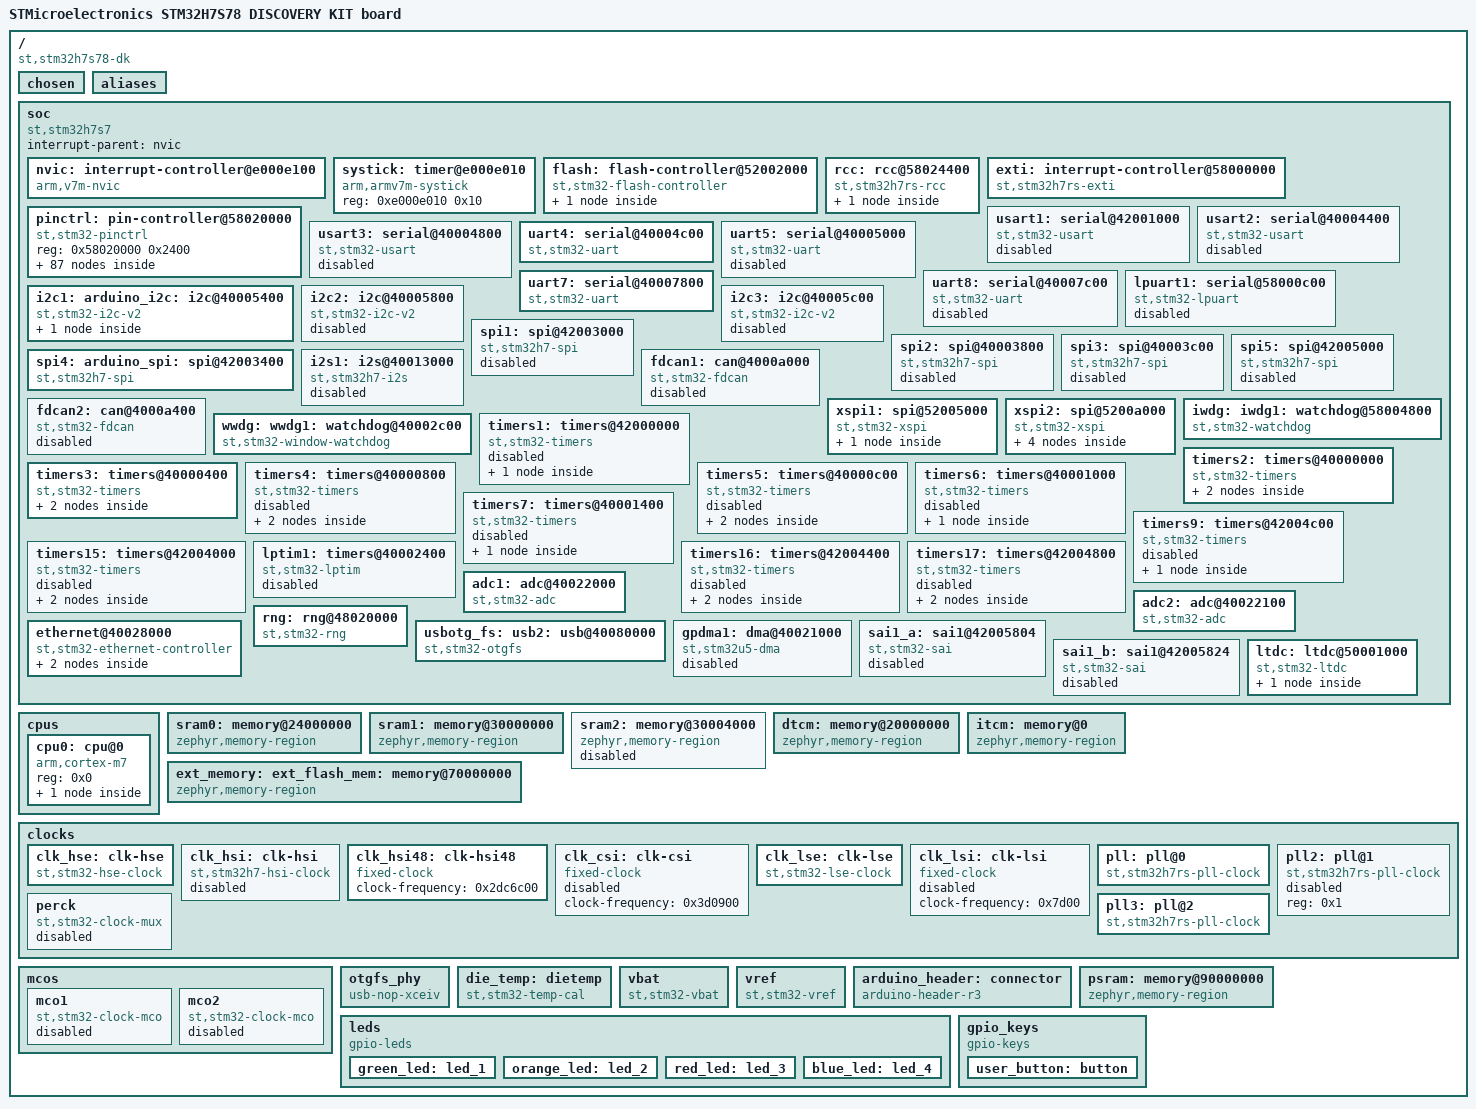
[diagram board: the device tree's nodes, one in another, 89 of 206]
/dts-v1/;

/* node '/' defined in zephyr/dts/common/skeleton.dtsi:9 */
/ {
	#address-cells = < 0x1 >;                                    /* in zephyr/dts/common/skeleton.dtsi:10 */
	#size-cells = < 0x1 >;                                       /* in zephyr/dts/common/skeleton.dtsi:11 */
	model = "STMicroelectronics STM32H7S78 DISCOVERY KIT board"; /* in zephyr/boards/st/stm32h7s78_dk/stm32h7s78_dk.dts:11 */
	compatible = "st,stm32h7s78-dk";                             /* in zephyr/boards/st/stm32h7s78_dk/stm32h7s78_dk.dts:12 */

	/* node '/chosen' defined in zephyr/dts/common/skeleton.dtsi:13 */
	chosen {
		zephyr,entropy = &rng;            /* in zephyr/dts/arm/st/h7rs/stm32h7rs.dtsi:30 */
		zephyr,console = &uart4;          /* in zephyr/boards/st/stm32h7s78_dk/stm32h7s78_dk-common.dtsi:16 */
		zephyr,shell-uart = &uart4;       /* in zephyr/boards/st/stm32h7s78_dk/stm32h7s78_dk-common.dtsi:17 */
		zephyr,sram = &sram0;             /* in zephyr/boards/st/stm32h7s78_dk/stm32h7s78_dk-common.dtsi:18 */
		zephyr,display = &ltdc;           /* in zephyr/boards/st/stm32h7s78_dk/stm32h7s78_dk-common.dtsi:19 */
		zephyr,touch = &display_ctp;      /* in zephyr/boards/st/stm32h7s78_dk/stm32h7s78_dk-common.dtsi:20 */
		zephyr,flash = &flash0;           /* in zephyr/boards/st/stm32h7s78_dk/stm32h7s78_dk.dts:15 */
		zephyr,flash-controller = &flash; /* in zephyr/boards/st/stm32h7s78_dk/stm32h7s78_dk.dts:16 */
	};

	/* node '/aliases' defined in zephyr/dts/common/skeleton.dtsi:15 */
	aliases {
		led0 = &blue_led;         /* in zephyr/boards/st/stm32h7s78_dk/stm32h7s78_dk-common.dtsi:65 */
		sw0 = &user_button;       /* in zephyr/boards/st/stm32h7s78_dk/stm32h7s78_dk-common.dtsi:66 */
		watchdog0 = &iwdg;        /* in zephyr/boards/st/stm32h7s78_dk/stm32h7s78_dk-common.dtsi:67 */
		die-temp0 = &die_temp;    /* in zephyr/boards/st/stm32h7s78_dk/stm32h7s78_dk-common.dtsi:68 */
		volt-sensor0 = &vref;     /* in zephyr/boards/st/stm32h7s78_dk/stm32h7s78_dk-common.dtsi:69 */
		volt-sensor1 = &vbat;     /* in zephyr/boards/st/stm32h7s78_dk/stm32h7s78_dk-common.dtsi:70 */
		spi-flash0 = &mx66uw1g45; /* in zephyr/boards/st/stm32h7s78_dk/stm32h7s78_dk-common.dtsi:71 */
	};

	/* node '/soc' defined in zephyr/dts/arm/armv7-m.dtsi:6 */
	soc {
		#address-cells = < 0x1 >;     /* in zephyr/dts/arm/armv7-m.dtsi:7 */
		#size-cells = < 0x1 >;        /* in zephyr/dts/arm/armv7-m.dtsi:8 */
		interrupt-parent = < &nvic >; /* in zephyr/dts/arm/armv7-m.dtsi:10 */
		ranges;                       /* in zephyr/dts/arm/armv7-m.dtsi:11 */
		compatible = "st,stm32h7s7",
		             "st,stm32h7rs",
		             "simple-bus";    /* in zephyr/dts/arm/st/h7rs/stm32h7s7.dtsi:14 */

		/* node '/soc/interrupt-controller@e000e100' defined in zephyr/dts/arm/armv7-m.dtsi:13 */
		nvic: interrupt-controller@e000e100 {
			#address-cells = < 0x1 >;            /* in zephyr/dts/arm/armv7-m.dtsi:14 */
			compatible = "arm,v7m-nvic";         /* in zephyr/dts/arm/armv7-m.dtsi:15 */
			reg = < 0xe000e100 0xc00 >;          /* in zephyr/dts/arm/armv7-m.dtsi:16 */
			interrupt-controller;                /* in zephyr/dts/arm/armv7-m.dtsi:17 */
			#interrupt-cells = < 0x2 >;          /* in zephyr/dts/arm/armv7-m.dtsi:18 */
			arm,num-irq-priority-bits = < 0x4 >; /* in zephyr/dts/arm/st/h7rs/stm32h7rs.dtsi:985 */
			phandle = < 0x1 >;                   /* in zephyr/dts/arm/armv7-m.dtsi:10 */
		};

		/* node '/soc/timer@e000e010' defined in zephyr/dts/arm/armv7-m.dtsi:21 */
		systick: timer@e000e010 {
			compatible = "arm,armv7m-systick"; /* in zephyr/dts/arm/armv7-m.dtsi:22 */
			reg = < 0xe000e010 0x10 >;         /* in zephyr/dts/arm/armv7-m.dtsi:23 */
		};

		/* node '/soc/flash-controller@52002000' defined in zephyr/dts/arm/st/h7rs/stm32h7rs.dtsi:187 */
		flash: flash-controller@52002000 {
			compatible = "st,stm32-flash-controller",
			             "st,stm32h7-flash-controller"; /* in zephyr/dts/arm/st/h7rs/stm32h7rs.dtsi:188 */
			reg = < 0x52002000 0x400 >;                 /* in zephyr/dts/arm/st/h7rs/stm32h7rs.dtsi:189 */
			interrupts = < 0x8 0x0 >;                   /* in zephyr/dts/arm/st/h7rs/stm32h7rs.dtsi:190 */
			#address-cells = < 0x1 >;                   /* in zephyr/dts/arm/st/h7rs/stm32h7rs.dtsi:192 */
			#size-cells = < 0x1 >;                      /* in zephyr/dts/arm/st/h7rs/stm32h7rs.dtsi:193 */

			/* node '/soc/flash-controller@52002000/flash@8000000' defined in zephyr/dts/arm/st/h7rs/stm32h7rs.dtsi:195 */
			flash0: flash@8000000 {
				compatible = "st,stm32-nv-flash",
				             "soc-nv-flash";      /* in zephyr/dts/arm/st/h7rs/stm32h7rs.dtsi:196 */
				write-block-size = < 0x20 >;      /* in zephyr/dts/arm/st/h7rs/stm32h7rs.dtsi:197 */
				erase-block-size = < 0x2000 >;    /* in zephyr/dts/arm/st/h7rs/stm32h7rs.dtsi:198 */
				max-erase-time = < 0x3 >;         /* in zephyr/dts/arm/st/h7rs/stm32h7rs.dtsi:200 */
				reg = < 0x8000000 0x10000 >;      /* in zephyr/dts/arm/st/h7rs/stm32h7s7X8.dtsi:13 */
			};
		};

		/* node '/soc/rcc@58024400' defined in zephyr/dts/arm/st/h7rs/stm32h7rs.dtsi:204 */
		rcc: rcc@58024400 {
			compatible = "st,stm32h7rs-rcc"; /* in zephyr/dts/arm/st/h7rs/stm32h7rs.dtsi:205 */
			#clock-cells = < 0x2 >;          /* in zephyr/dts/arm/st/h7rs/stm32h7rs.dtsi:206 */
			reg = < 0x58024400 0x400 >;      /* in zephyr/dts/arm/st/h7rs/stm32h7rs.dtsi:207 */
			clocks = < &pll >;               /* in zephyr/boards/st/stm32h7s78_dk/stm32h7s78_dk-common.dtsi:118 */
			clock-frequency = < 0xee6b280 >; /* in zephyr/boards/st/stm32h7s78_dk/stm32h7s78_dk-common.dtsi:119 */
			dcpre = < 0x1 >;                 /* in zephyr/boards/st/stm32h7s78_dk/stm32h7s78_dk-common.dtsi:120 */
			hpre = < 0x1 >;                  /* in zephyr/boards/st/stm32h7s78_dk/stm32h7s78_dk-common.dtsi:121 */
			ppre1 = < 0x2 >;                 /* in zephyr/boards/st/stm32h7s78_dk/stm32h7s78_dk-common.dtsi:122 */
			ppre2 = < 0x2 >;                 /* in zephyr/boards/st/stm32h7s78_dk/stm32h7s78_dk-common.dtsi:123 */
			ppre4 = < 0x2 >;                 /* in zephyr/boards/st/stm32h7s78_dk/stm32h7s78_dk-common.dtsi:124 */
			ppre5 = < 0x2 >;                 /* in zephyr/boards/st/stm32h7s78_dk/stm32h7s78_dk-common.dtsi:125 */
			phandle = < 0x3 >;               /* in zephyr/dts/arm/st/h7rs/stm32h7rs.dtsi:221 */

			/* node '/soc/rcc@58024400/reset-controller' defined in zephyr/dts/arm/st/h7rs/stm32h7rs.dtsi:209 */
			rctl: reset-controller {
				compatible = "st,stm32-rcc-rctl"; /* in zephyr/dts/arm/st/h7rs/stm32h7rs.dtsi:210 */
				#reset-cells = < 0x1 >;           /* in zephyr/dts/arm/st/h7rs/stm32h7rs.dtsi:211 */
				phandle = < 0x4 >;                /* in zephyr/dts/arm/st/h7rs/stm32h7rs.dtsi:345 */
			};
		};

		/* node '/soc/interrupt-controller@58000000' defined in zephyr/dts/arm/st/h7rs/stm32h7rs.dtsi:215 */
		exti: interrupt-controller@58000000 {
			compatible = "st,stm32h7rs-exti",
			             "st,stm32-exti";     /* in zephyr/dts/arm/st/h7rs/stm32h7rs.dtsi:216 */
			interrupt-controller;             /* in zephyr/dts/arm/st/h7rs/stm32h7rs.dtsi:217 */
			#interrupt-cells = < 0x1 >;       /* in zephyr/dts/arm/st/h7rs/stm32h7rs.dtsi:218 */
			#address-cells = < 0x0 >;         /* in zephyr/dts/arm/st/h7rs/stm32h7rs.dtsi:219 */
			reg = < 0x58000000 0x400 >;       /* in zephyr/dts/arm/st/h7rs/stm32h7rs.dtsi:220 */
			clocks = < &rcc 0x154 0x2 >;      /* in zephyr/dts/arm/st/h7rs/stm32h7rs.dtsi:221 */
			num-lines = < 0x40 >;             /* in zephyr/dts/arm/st/h7rs/stm32h7rs.dtsi:223 */
			interrupts = < 0x10 0x0 >,
			             < 0x11 0x0 >,
			             < 0x12 0x0 >,
			             < 0x13 0x0 >,
			             < 0x14 0x0 >,
			             < 0x15 0x0 >,
			             < 0x16 0x0 >,
			             < 0x17 0x0 >,
			             < 0x18 0x0 >,
			             < 0x19 0x0 >,
			             < 0x1a 0x0 >,
			             < 0x1b 0x0 >,
			             < 0x1c 0x0 >,
			             < 0x1d 0x0 >,
			             < 0x1e 0x0 >,
			             < 0x1f 0x0 >;        /* in zephyr/dts/arm/st/h7rs/stm32h7rs.dtsi:224 */
			interrupt-names = "line0",
			                  "line1",
			                  "line2",
			                  "line3",
			                  "line4",
			                  "line5",
			                  "line6",
			                  "line7",
			                  "line8",
			                  "line9",
			                  "line10",
			                  "line11",
			                  "line12",
			                  "line13",
			                  "line14",
			                  "line15";       /* in zephyr/dts/arm/st/h7rs/stm32h7rs.dtsi:228 */
			line-ranges = < 0x0 0x1 >,
			              < 0x1 0x1 >,
			              < 0x2 0x1 >,
			              < 0x3 0x1 >,
			              < 0x4 0x1 >,
			              < 0x5 0x1 >,
			              < 0x6 0x1 >,
			              < 0x7 0x1 >,
			              < 0x8 0x1 >,
			              < 0x9 0x1 >,
			              < 0xa 0x1 >,
			              < 0xb 0x1 >,
			              < 0xc 0x1 >,
			              < 0xd 0x1 >,
			              < 0xe 0x1 >,
			              < 0xf 0x1 >;        /* in zephyr/dts/arm/st/h7rs/stm32h7rs.dtsi:232 */
		};

		/* node '/soc/pin-controller@58020000' defined in zephyr/dts/arm/st/h7rs/stm32h7rs.dtsi:238 */
		pinctrl: pin-controller@58020000 {
			compatible = "st,stm32-pinctrl"; /* in zephyr/dts/arm/st/h7rs/stm32h7rs.dtsi:239 */
			#address-cells = < 0x1 >;        /* in zephyr/dts/arm/st/h7rs/stm32h7rs.dtsi:240 */
			#size-cells = < 0x1 >;           /* in zephyr/dts/arm/st/h7rs/stm32h7rs.dtsi:241 */
			reg = < 0x58020000 0x2400 >;     /* in zephyr/dts/arm/st/h7rs/stm32h7rs.dtsi:242 */

			/* node '/soc/pin-controller@58020000/gpio@58020000' defined in zephyr/dts/arm/st/h7rs/stm32h7rs.dtsi:244 */
			gpioa: gpio@58020000 {
				compatible = "st,stm32-gpio"; /* in zephyr/dts/arm/st/h7rs/stm32h7rs.dtsi:245 */
				gpio-controller;              /* in zephyr/dts/arm/st/h7rs/stm32h7rs.dtsi:246 */
				#gpio-cells = < 0x2 >;        /* in zephyr/dts/arm/st/h7rs/stm32h7rs.dtsi:247 */
				reg = < 0x58020000 0x400 >;   /* in zephyr/dts/arm/st/h7rs/stm32h7rs.dtsi:248 */
				clocks = < &rcc 0x140 0x1 >;  /* in zephyr/dts/arm/st/h7rs/stm32h7rs.dtsi:249 */
			};

			/* node '/soc/pin-controller@58020000/gpio@58020400' defined in zephyr/dts/arm/st/h7rs/stm32h7rs.dtsi:252 */
			gpiob: gpio@58020400 {
				compatible = "st,stm32-gpio"; /* in zephyr/dts/arm/st/h7rs/stm32h7rs.dtsi:253 */
				gpio-controller;              /* in zephyr/dts/arm/st/h7rs/stm32h7rs.dtsi:254 */
				#gpio-cells = < 0x2 >;        /* in zephyr/dts/arm/st/h7rs/stm32h7rs.dtsi:255 */
				reg = < 0x58020400 0x400 >;   /* in zephyr/dts/arm/st/h7rs/stm32h7rs.dtsi:256 */
				clocks = < &rcc 0x140 0x2 >;  /* in zephyr/dts/arm/st/h7rs/stm32h7rs.dtsi:257 */
				phandle = < 0x5a >;           /* in zephyr/boards/st/stm32h7s78_dk/arduino_r3_connector.dtsi:15 */
			};

			/* node '/soc/pin-controller@58020000/gpio@58020800' defined in zephyr/dts/arm/st/h7rs/stm32h7rs.dtsi:260 */
			gpioc: gpio@58020800 {
				compatible = "st,stm32-gpio"; /* in zephyr/dts/arm/st/h7rs/stm32h7rs.dtsi:261 */
				gpio-controller;              /* in zephyr/dts/arm/st/h7rs/stm32h7rs.dtsi:262 */
				#gpio-cells = < 0x2 >;        /* in zephyr/dts/arm/st/h7rs/stm32h7rs.dtsi:263 */
				reg = < 0x58020800 0x400 >;   /* in zephyr/dts/arm/st/h7rs/stm32h7rs.dtsi:264 */
				clocks = < &rcc 0x140 0x4 >;  /* in zephyr/dts/arm/st/h7rs/stm32h7rs.dtsi:265 */
				phandle = < 0x57 >;           /* in zephyr/boards/st/stm32h7s78_dk/arduino_r3_connector.dtsi:15 */
			};

			/* node '/soc/pin-controller@58020000/gpio@58020C00' defined in zephyr/dts/arm/st/h7rs/stm32h7rs.dtsi:268 */
			gpiod: gpio@58020C00 {
				compatible = "st,stm32-gpio"; /* in zephyr/dts/arm/st/h7rs/stm32h7rs.dtsi:269 */
				gpio-controller;              /* in zephyr/dts/arm/st/h7rs/stm32h7rs.dtsi:270 */
				#gpio-cells = < 0x2 >;        /* in zephyr/dts/arm/st/h7rs/stm32h7rs.dtsi:271 */
				reg = < 0x58020c00 0x400 >;   /* in zephyr/dts/arm/st/h7rs/stm32h7rs.dtsi:272 */
				clocks = < &rcc 0x140 0x8 >;  /* in zephyr/dts/arm/st/h7rs/stm32h7rs.dtsi:273 */
				phandle = < 0x59 >;           /* in zephyr/boards/st/stm32h7s78_dk/arduino_r3_connector.dtsi:15 */
			};

			/* node '/soc/pin-controller@58020000/gpio@58021000' defined in zephyr/dts/arm/st/h7rs/stm32h7rs.dtsi:276 */
			gpioe: gpio@58021000 {
				compatible = "st,stm32-gpio"; /* in zephyr/dts/arm/st/h7rs/stm32h7rs.dtsi:277 */
				gpio-controller;              /* in zephyr/dts/arm/st/h7rs/stm32h7rs.dtsi:278 */
				#gpio-cells = < 0x2 >;        /* in zephyr/dts/arm/st/h7rs/stm32h7rs.dtsi:279 */
				reg = < 0x58021000 0x400 >;   /* in zephyr/dts/arm/st/h7rs/stm32h7rs.dtsi:280 */
				clocks = < &rcc 0x140 0x10 >; /* in zephyr/dts/arm/st/h7rs/stm32h7rs.dtsi:281 */
				phandle = < 0xb >;            /* in zephyr/boards/st/stm32h7s78_dk/stm32h7s78_dk-common.dtsi:207 */
			};

			/* node '/soc/pin-controller@58020000/gpio@58021400' defined in zephyr/dts/arm/st/h7rs/stm32h7rs.dtsi:284 */
			gpiof: gpio@58021400 {
				compatible = "st,stm32-gpio"; /* in zephyr/dts/arm/st/h7rs/stm32h7rs.dtsi:285 */
				gpio-controller;              /* in zephyr/dts/arm/st/h7rs/stm32h7rs.dtsi:286 */
				#gpio-cells = < 0x2 >;        /* in zephyr/dts/arm/st/h7rs/stm32h7rs.dtsi:287 */
				reg = < 0x58021400 0x400 >;   /* in zephyr/dts/arm/st/h7rs/stm32h7rs.dtsi:288 */
				clocks = < &rcc 0x140 0x20 >; /* in zephyr/dts/arm/st/h7rs/stm32h7rs.dtsi:289 */
				phandle = < 0x58 >;           /* in zephyr/boards/st/stm32h7s78_dk/arduino_r3_connector.dtsi:15 */
			};

			/* node '/soc/pin-controller@58020000/gpio@58021800' defined in zephyr/dts/arm/st/h7rs/stm32h7rs.dtsi:292 */
			gpiog: gpio@58021800 {
				compatible = "st,stm32-gpio"; /* in zephyr/dts/arm/st/h7rs/stm32h7rs.dtsi:293 */
				gpio-controller;              /* in zephyr/dts/arm/st/h7rs/stm32h7rs.dtsi:294 */
				#gpio-cells = < 0x2 >;        /* in zephyr/dts/arm/st/h7rs/stm32h7rs.dtsi:295 */
				reg = < 0x58021800 0x400 >;   /* in zephyr/dts/arm/st/h7rs/stm32h7rs.dtsi:296 */
				clocks = < &rcc 0x140 0x40 >; /* in zephyr/dts/arm/st/h7rs/stm32h7rs.dtsi:297 */
				phandle = < 0x53 >;           /* in zephyr/boards/st/stm32h7s78_dk/stm32h7s78_dk-common.dtsi:310 */
			};

			/* node '/soc/pin-controller@58020000/gpio@58021c00' defined in zephyr/dts/arm/st/h7rs/stm32h7rs.dtsi:300 */
			gpioh: gpio@58021c00 {
				compatible = "st,stm32-gpio"; /* in zephyr/dts/arm/st/h7rs/stm32h7rs.dtsi:301 */
				gpio-controller;              /* in zephyr/dts/arm/st/h7rs/stm32h7rs.dtsi:302 */
				#gpio-cells = < 0x2 >;        /* in zephyr/dts/arm/st/h7rs/stm32h7rs.dtsi:303 */
				reg = < 0x58021c00 0x400 >;   /* in zephyr/dts/arm/st/h7rs/stm32h7rs.dtsi:304 */
				clocks = < &rcc 0x140 0x80 >; /* in zephyr/dts/arm/st/h7rs/stm32h7rs.dtsi:305 */
			};

			/* node '/soc/pin-controller@58020000/gpio@58023000' defined in zephyr/dts/arm/st/h7rs/stm32h7rs.dtsi:308 */
			gpiom: gpio@58023000 {
				compatible = "st,stm32-gpio";   /* in zephyr/dts/arm/st/h7rs/stm32h7rs.dtsi:309 */
				gpio-controller;                /* in zephyr/dts/arm/st/h7rs/stm32h7rs.dtsi:310 */
				#gpio-cells = < 0x2 >;          /* in zephyr/dts/arm/st/h7rs/stm32h7rs.dtsi:311 */
				reg = < 0x58023000 0x400 >;     /* in zephyr/dts/arm/st/h7rs/stm32h7rs.dtsi:312 */
				clocks = < &rcc 0x140 0x1000 >; /* in zephyr/dts/arm/st/h7rs/stm32h7rs.dtsi:313 */
				phandle = < 0x5c >;             /* in zephyr/boards/st/stm32h7s78_dk/stm32h7s78_dk-common.dtsi:44 */
			};

			/* node '/soc/pin-controller@58020000/gpio@58023400' defined in zephyr/dts/arm/st/h7rs/stm32h7rs.dtsi:316 */
			gpion: gpio@58023400 {
				compatible = "st,stm32-gpio";   /* in zephyr/dts/arm/st/h7rs/stm32h7rs.dtsi:317 */
				gpio-controller;                /* in zephyr/dts/arm/st/h7rs/stm32h7rs.dtsi:318 */
				#gpio-cells = < 0x2 >;          /* in zephyr/dts/arm/st/h7rs/stm32h7rs.dtsi:319 */
				reg = < 0x58023400 0x400 >;     /* in zephyr/dts/arm/st/h7rs/stm32h7rs.dtsi:320 */
				clocks = < &rcc 0x140 0x2000 >; /* in zephyr/dts/arm/st/h7rs/stm32h7rs.dtsi:321 */
			};

			/* node '/soc/pin-controller@58020000/gpio@58023800' defined in zephyr/dts/arm/st/h7rs/stm32h7rs.dtsi:324 */
			gpioo: gpio@58023800 {
				compatible = "st,stm32-gpio";   /* in zephyr/dts/arm/st/h7rs/stm32h7rs.dtsi:325 */
				gpio-controller;                /* in zephyr/dts/arm/st/h7rs/stm32h7rs.dtsi:326 */
				#gpio-cells = < 0x2 >;          /* in zephyr/dts/arm/st/h7rs/stm32h7rs.dtsi:327 */
				reg = < 0x58023800 0x400 >;     /* in zephyr/dts/arm/st/h7rs/stm32h7rs.dtsi:328 */
				clocks = < &rcc 0x140 0x4000 >; /* in zephyr/dts/arm/st/h7rs/stm32h7rs.dtsi:329 */
				phandle = < 0x5b >;             /* in zephyr/boards/st/stm32h7s78_dk/stm32h7s78_dk-common.dtsi:34 */
			};

			/* node '/soc/pin-controller@58020000/gpio@58023c00' defined in zephyr/dts/arm/st/h7rs/stm32h7rs.dtsi:332 */
			gpiop: gpio@58023c00 {
				compatible = "st,stm32-gpio";   /* in zephyr/dts/arm/st/h7rs/stm32h7rs.dtsi:333 */
				gpio-controller;                /* in zephyr/dts/arm/st/h7rs/stm32h7rs.dtsi:334 */
				#gpio-cells = < 0x2 >;          /* in zephyr/dts/arm/st/h7rs/stm32h7rs.dtsi:335 */
				reg = < 0x58023c00 0x400 >;     /* in zephyr/dts/arm/st/h7rs/stm32h7rs.dtsi:336 */
				clocks = < &rcc 0x140 0x8000 >; /* in zephyr/dts/arm/st/h7rs/stm32h7rs.dtsi:337 */
			};

			/* node '/soc/pin-controller@58020000/adc1_inp6_pf12' defined in modules/hal/stm32/dts/st/h7/stm32h7s7l8hxh-pinctrl.dtsi:111 */
			adc1_inp6_pf12: adc1_inp6_pf12 {
				pinmux = < 0xb90 >; /* in modules/hal/stm32/dts/st/h7/stm32h7s7l8hxh-pinctrl.dtsi:112 */
				phandle = < 0x31 >; /* in zephyr/boards/st/stm32h7s78_dk/stm32h7s78_dk-common.dtsi:177 */
			};

			/* node '/soc/pin-controller@58020000/adc2_inp2_pf13' defined in modules/hal/stm32/dts/st/h7/stm32h7s7l8hxh-pinctrl.dtsi:203 */
			adc2_inp2_pf13: adc2_inp2_pf13 {
				pinmux = < 0xbb0 >; /* in modules/hal/stm32/dts/st/h7/stm32h7s7l8hxh-pinctrl.dtsi:204 */
				phandle = < 0x32 >; /* in zephyr/boards/st/stm32h7s78_dk/stm32h7s78_dk-common.dtsi:185 */
			};

			/* node '/soc/pin-controller@58020000/i2c1_scl_pb6' defined in modules/hal/stm32/dts/st/h7/stm32h7s7l8hxh-pinctrl.dtsi:1971 */
			i2c1_scl_pb6: i2c1_scl_pb6 {
				pinmux = < 0x2c4 >; /* in modules/hal/stm32/dts/st/h7/stm32h7s7l8hxh-pinctrl.dtsi:1972 */
				bias-pull-up;       /* in modules/hal/stm32/dts/st/h7/stm32h7s7l8hxh-pinctrl.dtsi:1973 */
				drive-open-drain;   /* in modules/hal/stm32/dts/st/h7/stm32h7s7l8hxh-pinctrl.dtsi:1974 */
				phandle = < 0x9 >;  /* in zephyr/boards/st/stm32h7s78_dk/stm32h7s78_dk-common.dtsi:200 */
			};

			/* node '/soc/pin-controller@58020000/i2c1_sda_pb9' defined in modules/hal/stm32/dts/st/h7/stm32h7s7l8hxh-pinctrl.dtsi:2009 */
			i2c1_sda_pb9: i2c1_sda_pb9 {
				pinmux = < 0x324 >; /* in modules/hal/stm32/dts/st/h7/stm32h7s7l8hxh-pinctrl.dtsi:2010 */
				bias-pull-up;       /* in modules/hal/stm32/dts/st/h7/stm32h7s7l8hxh-pinctrl.dtsi:2011 */
				drive-open-drain;   /* in modules/hal/stm32/dts/st/h7/stm32h7s7l8hxh-pinctrl.dtsi:2012 */
				phandle = < 0xa >;  /* in zephyr/boards/st/stm32h7s78_dk/stm32h7s78_dk-common.dtsi:200 */
			};

			/* node '/soc/pin-controller@58020000/ltdc_g3_pa0' defined in modules/hal/stm32/dts/st/h7/stm32h7s7l8hxh-pinctrl.dtsi:2254 */
			ltdc_g3_pa0: ltdc_g3_pa0 {
				pinmux = < 0xd >;   /* in modules/hal/stm32/dts/st/h7/stm32h7s7l8hxh-pinctrl.dtsi:2255 */
				phandle = < 0x42 >; /* in zephyr/boards/st/stm32h7s78_dk/stm32h7s78_dk-common.dtsi:301 */
			};

			/* node '/soc/pin-controller@58020000/ltdc_g2_pa1' defined in modules/hal/stm32/dts/st/h7/stm32h7s7l8hxh-pinctrl.dtsi:2258 */
			ltdc_g2_pa1: ltdc_g2_pa1 {
				pinmux = < 0x2d >;  /* in modules/hal/stm32/dts/st/h7/stm32h7s7l8hxh-pinctrl.dtsi:2259 */
				phandle = < 0x41 >; /* in zephyr/boards/st/stm32h7s78_dk/stm32h7s78_dk-common.dtsi:301 */
			};

			/* node '/soc/pin-controller@58020000/ltdc_b7_pa6' defined in modules/hal/stm32/dts/st/h7/stm32h7s7l8hxh-pinctrl.dtsi:2278 */
			ltdc_b7_pa6: ltdc_b7_pa6 {
				pinmux = < 0xcc >;  /* in modules/hal/stm32/dts/st/h7/stm32h7s7l8hxh-pinctrl.dtsi:2279 */
				phandle = < 0x4e >; /* in zephyr/boards/st/stm32h7s78_dk/stm32h7s78_dk-common.dtsi:301 */
			};

			/* node '/soc/pin-controller@58020000/ltdc_b6_pa8' defined in modules/hal/stm32/dts/st/h7/stm32h7s7l8hxh-pinctrl.dtsi:2294 */
			ltdc_b6_pa8: ltdc_b6_pa8 {
				pinmux = < 0x10d >; /* in modules/hal/stm32/dts/st/h7/stm32h7s7l8hxh-pinctrl.dtsi:2295 */
				phandle = < 0x4d >; /* in zephyr/boards/st/stm32h7s78_dk/stm32h7s78_dk-common.dtsi:301 */
			};

			/* node '/soc/pin-controller@58020000/ltdc_b5_pa9' defined in modules/hal/stm32/dts/st/h7/stm32h7s7l8hxh-pinctrl.dtsi:2298 */
			ltdc_b5_pa9: ltdc_b5_pa9 {
				pinmux = < 0x12e >; /* in modules/hal/stm32/dts/st/h7/stm32h7s7l8hxh-pinctrl.dtsi:2299 */
				phandle = < 0x4c >; /* in zephyr/boards/st/stm32h7s78_dk/stm32h7s78_dk-common.dtsi:301 */
			};

			/* node '/soc/pin-controller@58020000/ltdc_b4_pa10' defined in modules/hal/stm32/dts/st/h7/stm32h7s7l8hxh-pinctrl.dtsi:2302 */
			ltdc_b4_pa10: ltdc_b4_pa10 {
				pinmux = < 0x14e >; /* in modules/hal/stm32/dts/st/h7/stm32h7s7l8hxh-pinctrl.dtsi:2303 */
				phandle = < 0x4b >; /* in zephyr/boards/st/stm32h7s78_dk/stm32h7s78_dk-common.dtsi:301 */
			};

			/* node '/soc/pin-controller@58020000/ltdc_b3_pa11' defined in modules/hal/stm32/dts/st/h7/stm32h7s7l8hxh-pinctrl.dtsi:2306 */
			ltdc_b3_pa11: ltdc_b3_pa11 {
				pinmux = < 0x16d >; /* in modules/hal/stm32/dts/st/h7/stm32h7s7l8hxh-pinctrl.dtsi:2307 */
				phandle = < 0x4a >; /* in zephyr/boards/st/stm32h7s78_dk/stm32h7s78_dk-common.dtsi:301 */
			};

			/* node '/soc/pin-controller@58020000/ltdc_b2_pa12' defined in modules/hal/stm32/dts/st/h7/stm32h7s7l8hxh-pinctrl.dtsi:2310 */
			ltdc_b2_pa12: ltdc_b2_pa12 {
				pinmux = < 0x18d >; /* in modules/hal/stm32/dts/st/h7/stm32h7s7l8hxh-pinctrl.dtsi:2311 */
				phandle = < 0x49 >; /* in zephyr/boards/st/stm32h7s78_dk/stm32h7s78_dk-common.dtsi:301 */
			};

			/* node '/soc/pin-controller@58020000/ltdc_r5_pa15' defined in modules/hal/stm32/dts/st/h7/stm32h7s7l8hxh-pinctrl.dtsi:2314 */
			ltdc_r5_pa15: ltdc_r5_pa15 {
				pinmux = < 0x1ed >; /* in modules/hal/stm32/dts/st/h7/stm32h7s7l8hxh-pinctrl.dtsi:2315 */
				phandle = < 0x3c >; /* in zephyr/boards/st/stm32h7s78_dk/stm32h7s78_dk-common.dtsi:301 */
			};

			/* node '/soc/pin-controller@58020000/ltdc_r4_pb3' defined in modules/hal/stm32/dts/st/h7/stm32h7s7l8hxh-pinctrl.dtsi:2330 */
			ltdc_r4_pb3: ltdc_r4_pb3 {
				pinmux = < 0x26d >; /* in modules/hal/stm32/dts/st/h7/stm32h7s7l8hxh-pinctrl.dtsi:2331 */
				phandle = < 0x3b >; /* in zephyr/boards/st/stm32h7s78_dk/stm32h7s78_dk-common.dtsi:301 */
			};

			/* node '/soc/pin-controller@58020000/ltdc_r3_pb4' defined in modules/hal/stm32/dts/st/h7/stm32h7s7l8hxh-pinctrl.dtsi:2334 */
			ltdc_r3_pb4: ltdc_r3_pb4 {
				pinmux = < 0x28d >; /* in modules/hal/stm32/dts/st/h7/stm32h7s7l8hxh-pinctrl.dtsi:2335 */
				phandle = < 0x3a >; /* in zephyr/boards/st/stm32h7s78_dk/stm32h7s78_dk-common.dtsi:301 */
			};

			/* node '/soc/pin-controller@58020000/ltdc_g6_pb11' defined in modules/hal/stm32/dts/st/h7/stm32h7s7l8hxh-pinctrl.dtsi:2346 */
			ltdc_g6_pb11: ltdc_g6_pb11 {
				pinmux = < 0x36d >; /* in modules/hal/stm32/dts/st/h7/stm32h7s7l8hxh-pinctrl.dtsi:2347 */
				phandle = < 0x45 >; /* in zephyr/boards/st/stm32h7s78_dk/stm32h7s78_dk-common.dtsi:301 */
			};

			/* node '/soc/pin-controller@58020000/ltdc_g5_pb12' defined in modules/hal/stm32/dts/st/h7/stm32h7s7l8hxh-pinctrl.dtsi:2350 */
			ltdc_g5_pb12: ltdc_g5_pb12 {
				pinmux = < 0x38d >; /* in modules/hal/stm32/dts/st/h7/stm32h7s7l8hxh-pinctrl.dtsi:2351 */
				phandle = < 0x44 >; /* in zephyr/boards/st/stm32h7s78_dk/stm32h7s78_dk-common.dtsi:301 */
			};

			/* node '/soc/pin-controller@58020000/ltdc_g4_pb13' defined in modules/hal/stm32/dts/st/h7/stm32h7s7l8hxh-pinctrl.dtsi:2354 */
			ltdc_g4_pb13: ltdc_g4_pb13 {
				pinmux = < 0x3aa >; /* in modules/hal/stm32/dts/st/h7/stm32h7s7l8hxh-pinctrl.dtsi:2355 */
				phandle = < 0x43 >; /* in zephyr/boards/st/stm32h7s78_dk/stm32h7s78_dk-common.dtsi:301 */
			};

			/* node '/soc/pin-controller@58020000/ltdc_de_pb14' defined in modules/hal/stm32/dts/st/h7/stm32h7s7l8hxh-pinctrl.dtsi:2358 */
			ltdc_de_pb14: ltdc_de_pb14 {
				pinmux = < 0x3cd >; /* in modules/hal/stm32/dts/st/h7/stm32h7s7l8hxh-pinctrl.dtsi:2359 */
				phandle = < 0x4f >; /* in zephyr/boards/st/stm32h7s78_dk/stm32h7s78_dk-common.dtsi:301 */
			};

			/* node '/soc/pin-controller@58020000/ltdc_g7_pb15' defined in modules/hal/stm32/dts/st/h7/stm32h7s7l8hxh-pinctrl.dtsi:2362 */
			ltdc_g7_pb15: ltdc_g7_pb15 {
				pinmux = < 0x3ea >; /* in modules/hal/stm32/dts/st/h7/stm32h7s7l8hxh-pinctrl.dtsi:2363 */
				phandle = < 0x46 >; /* in zephyr/boards/st/stm32h7s78_dk/stm32h7s78_dk-common.dtsi:301 */
			};

			/* node '/soc/pin-controller@58020000/ltdc_vsync_pe11' defined in modules/hal/stm32/dts/st/h7/stm32h7s7l8hxh-pinctrl.dtsi:2374 */
			ltdc_vsync_pe11: ltdc_vsync_pe11 {
				pinmux = < 0x96b >; /* in modules/hal/stm32/dts/st/h7/stm32h7s7l8hxh-pinctrl.dtsi:2375 */
				phandle = < 0x52 >; /* in zephyr/boards/st/stm32h7s78_dk/stm32h7s78_dk-common.dtsi:301 */
			};

			/* node '/soc/pin-controller@58020000/ltdc_r2_pf0' defined in modules/hal/stm32/dts/st/h7/stm32h7s7l8hxh-pinctrl.dtsi:2378 */
			ltdc_r2_pf0: ltdc_r2_pf0 {
				pinmux = < 0xa0b >; /* in modules/hal/stm32/dts/st/h7/stm32h7s7l8hxh-pinctrl.dtsi:2379 */
				phandle = < 0x39 >; /* in zephyr/boards/st/stm32h7s78_dk/stm32h7s78_dk-common.dtsi:301 */
			};

			/* node '/soc/pin-controller@58020000/ltdc_g0_pf7' defined in modules/hal/stm32/dts/st/h7/stm32h7s7l8hxh-pinctrl.dtsi:2382 */
			ltdc_g0_pf7: ltdc_g0_pf7 {
				pinmux = < 0xaed >; /* in modules/hal/stm32/dts/st/h7/stm32h7s7l8hxh-pinctrl.dtsi:2383 */
				phandle = < 0x3f >; /* in zephyr/boards/st/stm32h7s78_dk/stm32h7s78_dk-common.dtsi:301 */
			};

			/* node '/soc/pin-controller@58020000/ltdc_r0_pf9' defined in modules/hal/stm32/dts/st/h7/stm32h7s7l8hxh-pinctrl.dtsi:2390 */
			ltdc_r0_pf9: ltdc_r0_pf9 {
				pinmux = < 0xb2d >; /* in modules/hal/stm32/dts/st/h7/stm32h7s7l8hxh-pinctrl.dtsi:2391 */
				phandle = < 0x37 >; /* in zephyr/boards/st/stm32h7s78_dk/stm32h7s78_dk-common.dtsi:301 */
			};

			/* node '/soc/pin-controller@58020000/ltdc_r1_pf10' defined in modules/hal/stm32/dts/st/h7/stm32h7s7l8hxh-pinctrl.dtsi:2394 */
			ltdc_r1_pf10: ltdc_r1_pf10 {
				pinmux = < 0xb4e >; /* in modules/hal/stm32/dts/st/h7/stm32h7s7l8hxh-pinctrl.dtsi:2395 */
				phandle = < 0x38 >; /* in zephyr/boards/st/stm32h7s78_dk/stm32h7s78_dk-common.dtsi:301 */
			};

			/* node '/soc/pin-controller@58020000/ltdc_b0_pf11' defined in modules/hal/stm32/dts/st/h7/stm32h7s7l8hxh-pinctrl.dtsi:2398 */
			ltdc_b0_pf11: ltdc_b0_pf11 {
				pinmux = < 0xb6e >; /* in modules/hal/stm32/dts/st/h7/stm32h7s7l8hxh-pinctrl.dtsi:2399 */
				phandle = < 0x47 >; /* in zephyr/boards/st/stm32h7s78_dk/stm32h7s78_dk-common.dtsi:301 */
			};

			/* node '/soc/pin-controller@58020000/ltdc_g1_pf15' defined in modules/hal/stm32/dts/st/h7/stm32h7s7l8hxh-pinctrl.dtsi:2406 */
			ltdc_g1_pf15: ltdc_g1_pf15 {
				pinmux = < 0xbed >; /* in modules/hal/stm32/dts/st/h7/stm32h7s7l8hxh-pinctrl.dtsi:2407 */
				phandle = < 0x40 >; /* in zephyr/boards/st/stm32h7s78_dk/stm32h7s78_dk-common.dtsi:301 */
			};

			/* node '/soc/pin-controller@58020000/ltdc_r7_pg0' defined in modules/hal/stm32/dts/st/h7/stm32h7s7l8hxh-pinctrl.dtsi:2410 */
			ltdc_r7_pg0: ltdc_r7_pg0 {
				pinmux = < 0xc0d >; /* in modules/hal/stm32/dts/st/h7/stm32h7s7l8hxh-pinctrl.dtsi:2411 */
				phandle = < 0x3e >; /* in zephyr/boards/st/stm32h7s78_dk/stm32h7s78_dk-common.dtsi:301 */
			};

			/* node '/soc/pin-controller@58020000/ltdc_r6_pg1' defined in modules/hal/stm32/dts/st/h7/stm32h7s7l8hxh-pinctrl.dtsi:2414 */
			ltdc_r6_pg1: ltdc_r6_pg1 {
				pinmux = < 0xc2d >; /* in modules/hal/stm32/dts/st/h7/stm32h7s7l8hxh-pinctrl.dtsi:2415 */
				phandle = < 0x3d >; /* in zephyr/boards/st/stm32h7s78_dk/stm32h7s78_dk-common.dtsi:301 */
			};

			/* node '/soc/pin-controller@58020000/ltdc_hsync_pg2' defined in modules/hal/stm32/dts/st/h7/stm32h7s7l8hxh-pinctrl.dtsi:2418 */
			ltdc_hsync_pg2: ltdc_hsync_pg2 {
				pinmux = < 0xc4d >; /* in modules/hal/stm32/dts/st/h7/stm32h7s7l8hxh-pinctrl.dtsi:2419 */
				phandle = < 0x51 >; /* in zephyr/boards/st/stm32h7s78_dk/stm32h7s78_dk-common.dtsi:301 */
			};

			/* node '/soc/pin-controller@58020000/ltdc_clk_pg13' defined in modules/hal/stm32/dts/st/h7/stm32h7s7l8hxh-pinctrl.dtsi:2426 */
			ltdc_clk_pg13: ltdc_clk_pg13 {
				pinmux = < 0xdad >; /* in modules/hal/stm32/dts/st/h7/stm32h7s7l8hxh-pinctrl.dtsi:2427 */
				phandle = < 0x50 >; /* in zephyr/boards/st/stm32h7s78_dk/stm32h7s78_dk-common.dtsi:301 */
			};

			/* node '/soc/pin-controller@58020000/ltdc_b1_pg14' defined in modules/hal/stm32/dts/st/h7/stm32h7s7l8hxh-pinctrl.dtsi:2430 */
			ltdc_b1_pg14: ltdc_b1_pg14 {
				pinmux = < 0xdcd >; /* in modules/hal/stm32/dts/st/h7/stm32h7s7l8hxh-pinctrl.dtsi:2431 */
				phandle = < 0x48 >; /* in zephyr/boards/st/stm32h7s78_dk/stm32h7s78_dk-common.dtsi:301 */
			};

			/* node '/soc/pin-controller@58020000/spi4_miso_pe13' defined in modules/hal/stm32/dts/st/h7/stm32h7s7l8hxh-pinctrl.dtsi:2817 */
			spi4_miso_pe13: spi4_miso_pe13 {
				pinmux = < 0x9a5 >; /* in modules/hal/stm32/dts/st/h7/stm32h7s7l8hxh-pinctrl.dtsi:2818 */
				bias-pull-down;     /* in modules/hal/stm32/dts/st/h7/stm32h7s7l8hxh-pinctrl.dtsi:2819 */
				phandle = < 0xe >;  /* in zephyr/boards/st/stm32h7s78_dk/stm32h7s78_dk-common.dtsi:193 */
			};

			/* node '/soc/pin-controller@58020000/spi4_mosi_pe14' defined in modules/hal/stm32/dts/st/h7/stm32h7s7l8hxh-pinctrl.dtsi:2909 */
			spi4_mosi_pe14: spi4_mosi_pe14 {
				pinmux = < 0x9c5 >; /* in modules/hal/stm32/dts/st/h7/stm32h7s7l8hxh-pinctrl.dtsi:2910 */
				bias-pull-down;     /* in modules/hal/stm32/dts/st/h7/stm32h7s7l8hxh-pinctrl.dtsi:2911 */
				phandle = < 0xf >;  /* in zephyr/boards/st/stm32h7s78_dk/stm32h7s78_dk-common.dtsi:193 */
			};

			/* node '/soc/pin-controller@58020000/spi4_nss_pe4' defined in modules/hal/stm32/dts/st/h7/stm32h7s7l8hxh-pinctrl.dtsi:2991 */
			spi4_nss_pe4: spi4_nss_pe4 {
				pinmux = < 0x885 >; /* in modules/hal/stm32/dts/st/h7/stm32h7s7l8hxh-pinctrl.dtsi:2992 */
				bias-pull-up;       /* in modules/hal/stm32/dts/st/h7/stm32h7s7l8hxh-pinctrl.dtsi:2993 */
				phandle = < 0xc >;  /* in zephyr/boards/st/stm32h7s78_dk/stm32h7s78_dk-common.dtsi:193 */
			};

			/* node '/soc/pin-controller@58020000/spi4_sck_pe12' defined in modules/hal/stm32/dts/st/h7/stm32h7s7l8hxh-pinctrl.dtsi:3105 */
			spi4_sck_pe12: spi4_sck_pe12 {
				pinmux = < 0x985 >;            /* in modules/hal/stm32/dts/st/h7/stm32h7s7l8hxh-pinctrl.dtsi:3106 */
				bias-pull-down;                /* in modules/hal/stm32/dts/st/h7/stm32h7s7l8hxh-pinctrl.dtsi:3107 */
				slew-rate = "very-high-speed"; /* in modules/hal/stm32/dts/st/h7/stm32h7s7l8hxh-pinctrl.dtsi:3108 */
				phandle = < 0xd >;             /* in zephyr/boards/st/stm32h7s78_dk/stm32h7s78_dk-common.dtsi:193 */
			};

			/* node '/soc/pin-controller@58020000/tim2_ch4_pa3' defined in modules/hal/stm32/dts/st/h7/stm32h7s7l8hxh-pinctrl.dtsi:3313 */
			tim2_ch4_pa3: tim2_ch4_pa3 {
				pinmux = < 0x61 >;  /* in modules/hal/stm32/dts/st/h7/stm32h7s7l8hxh-pinctrl.dtsi:3314 */
				phandle = < 0x2f >; /* in zephyr/boards/st/stm32h7s78_dk/stm32h7s78_dk-common.dtsi:148 */
			};

			/* node '/soc/pin-controller@58020000/tim3_ch2_pb5' defined in modules/hal/stm32/dts/st/h7/stm32h7s7l8hxh-pinctrl.dtsi:3369 */
			tim3_ch2_pb5: tim3_ch2_pb5 {
				pinmux = < 0x2a2 >; /* in modules/hal/stm32/dts/st/h7/stm32h7s7l8hxh-pinctrl.dtsi:3370 */
				phandle = < 0x30 >; /* in zephyr/boards/st/stm32h7s78_dk/stm32h7s78_dk-common.dtsi:159 */
			};

			/* node '/soc/pin-controller@58020000/uart4_rx_pd0' defined in modules/hal/stm32/dts/st/h7/stm32h7s7l8hxh-pinctrl.dtsi:3787 */
			uart4_rx_pd0: uart4_rx_pd0 {
				pinmux = < 0x608 >; /* in modules/hal/stm32/dts/st/h7/stm32h7s7l8hxh-pinctrl.dtsi:3788 */
				phandle = < 0x6 >;  /* in zephyr/boards/st/stm32h7s78_dk/stm32h7s78_dk-common.dtsi:129 */
			};

			/* node '/soc/pin-controller@58020000/uart7_rx_pe7' defined in modules/hal/stm32/dts/st/h7/stm32h7s7l8hxh-pinctrl.dtsi:3811 */
			uart7_rx_pe7: uart7_rx_pe7 {
				pinmux = < 0x8e7 >; /* in modules/hal/stm32/dts/st/h7/stm32h7s7l8hxh-pinctrl.dtsi:3812 */
				phandle = < 0x8 >;  /* in zephyr/boards/st/stm32h7s78_dk/stm32h7s78_dk-common.dtsi:136 */
			};

			/* node '/soc/pin-controller@58020000/uart4_tx_pd1' defined in modules/hal/stm32/dts/st/h7/stm32h7s7l8hxh-pinctrl.dtsi:3899 */
			uart4_tx_pd1: uart4_tx_pd1 {
				pinmux = < 0x628 >; /* in modules/hal/stm32/dts/st/h7/stm32h7s7l8hxh-pinctrl.dtsi:3900 */
				bias-pull-up;       /* in modules/hal/stm32/dts/st/h7/stm32h7s7l8hxh-pinctrl.dtsi:3901 */
				phandle = < 0x5 >;  /* in zephyr/boards/st/stm32h7s78_dk/stm32h7s78_dk-common.dtsi:129 */
			};

			/* node '/soc/pin-controller@58020000/uart7_tx_pe8' defined in modules/hal/stm32/dts/st/h7/stm32h7s7l8hxh-pinctrl.dtsi:3934 */
			uart7_tx_pe8: uart7_tx_pe8 {
				pinmux = < 0x907 >; /* in modules/hal/stm32/dts/st/h7/stm32h7s7l8hxh-pinctrl.dtsi:3935 */
				bias-pull-up;       /* in modules/hal/stm32/dts/st/h7/stm32h7s7l8hxh-pinctrl.dtsi:3936 */
				phandle = < 0x7 >;  /* in zephyr/boards/st/stm32h7s78_dk/stm32h7s78_dk-common.dtsi:136 */
			};

			/* node '/soc/pin-controller@58020000/usb_otg_fs_dp_pm11' defined in modules/hal/stm32/dts/st/h7/stm32h7s7l8hxh-pinctrl.dtsi:3970 */
			usb_otg_fs_dp_pm11: usb_otg_fs_dp_pm11 {
				pinmux = < 0x196a >; /* in modules/hal/stm32/dts/st/h7/stm32h7s7l8hxh-pinctrl.dtsi:3971 */
				phandle = < 0x35 >;  /* in zephyr/boards/st/stm32h7s78_dk/stm32h7s78_dk-common.dtsi:293 */
			};

			/* node '/soc/pin-controller@58020000/usb_otg_fs_dm_pm12' defined in modules/hal/stm32/dts/st/h7/stm32h7s7l8hxh-pinctrl.dtsi:3974 */
			usb_otg_fs_dm_pm12: usb_otg_fs_dm_pm12 {
				pinmux = < 0x198a >; /* in modules/hal/stm32/dts/st/h7/stm32h7s7l8hxh-pinctrl.dtsi:3975 */
				phandle = < 0x34 >;  /* in zephyr/boards/st/stm32h7s78_dk/stm32h7s78_dk-common.dtsi:293 */
			};

			/* node '/soc/pin-controller@58020000/xspim_p2_dqs0_pn0' defined in modules/hal/stm32/dts/st/h7/stm32h7s7l8hxh-pinctrl.dtsi:4010 */
			xspim_p2_dqs0_pn0: xspim_p2_dqs0_pn0 {
				pinmux = < 0x1a09 >;           /* in modules/hal/stm32/dts/st/h7/stm32h7s7l8hxh-pinctrl.dtsi:4011 */
				slew-rate = "very-high-speed"; /* in modules/hal/stm32/dts/st/h7/stm32h7s7l8hxh-pinctrl.dtsi:4012 */
				phandle = < 0x2e >;            /* in zephyr/boards/st/stm32h7s78_dk/stm32h7s78_dk-common.dtsi:241 */
			};

			/* node '/soc/pin-controller@58020000/xspim_p2_ncs1_pn1' defined in modules/hal/stm32/dts/st/h7/stm32h7s7l8hxh-pinctrl.dtsi:4015 */
			xspim_p2_ncs1_pn1: xspim_p2_ncs1_pn1 {
				pinmux = < 0x1a29 >;           /* in modules/hal/stm32/dts/st/h7/stm32h7s7l8hxh-pinctrl.dtsi:4016 */
				slew-rate = "very-high-speed"; /* in modules/hal/stm32/dts/st/h7/stm32h7s7l8hxh-pinctrl.dtsi:4017 */
				phandle = < 0x25 >;            /* in zephyr/boards/st/stm32h7s78_dk/stm32h7s78_dk-common.dtsi:241 */
			};

			/* node '/soc/pin-controller@58020000/xspim_p2_io0_pn2' defined in modules/hal/stm32/dts/st/h7/stm32h7s7l8hxh-pinctrl.dtsi:4020 */
			xspim_p2_io0_pn2: xspim_p2_io0_pn2 {
				pinmux = < 0x1a49 >;           /* in modules/hal/stm32/dts/st/h7/stm32h7s7l8hxh-pinctrl.dtsi:4021 */
				slew-rate = "very-high-speed"; /* in modules/hal/stm32/dts/st/h7/stm32h7s7l8hxh-pinctrl.dtsi:4022 */
				phandle = < 0x26 >;            /* in zephyr/boards/st/stm32h7s78_dk/stm32h7s78_dk-common.dtsi:241 */
			};

			/* node '/soc/pin-controller@58020000/xspim_p2_io1_pn3' defined in modules/hal/stm32/dts/st/h7/stm32h7s7l8hxh-pinctrl.dtsi:4025 */
			xspim_p2_io1_pn3: xspim_p2_io1_pn3 {
				pinmux = < 0x1a69 >;           /* in modules/hal/stm32/dts/st/h7/stm32h7s7l8hxh-pinctrl.dtsi:4026 */
				slew-rate = "very-high-speed"; /* in modules/hal/stm32/dts/st/h7/stm32h7s7l8hxh-pinctrl.dtsi:4027 */
				phandle = < 0x27 >;            /* in zephyr/boards/st/stm32h7s78_dk/stm32h7s78_dk-common.dtsi:241 */
			};

			/* node '/soc/pin-controller@58020000/xspim_p2_io2_pn4' defined in modules/hal/stm32/dts/st/h7/stm32h7s7l8hxh-pinctrl.dtsi:4030 */
			xspim_p2_io2_pn4: xspim_p2_io2_pn4 {
				pinmux = < 0x1a89 >;           /* in modules/hal/stm32/dts/st/h7/stm32h7s7l8hxh-pinctrl.dtsi:4031 */
				slew-rate = "very-high-speed"; /* in modules/hal/stm32/dts/st/h7/stm32h7s7l8hxh-pinctrl.dtsi:4032 */
				phandle = < 0x28 >;            /* in zephyr/boards/st/stm32h7s78_dk/stm32h7s78_dk-common.dtsi:241 */
			};

			/* node '/soc/pin-controller@58020000/xspim_p2_io3_pn5' defined in modules/hal/stm32/dts/st/h7/stm32h7s7l8hxh-pinctrl.dtsi:4035 */
			xspim_p2_io3_pn5: xspim_p2_io3_pn5 {
				pinmux = < 0x1aa9 >;           /* in modules/hal/stm32/dts/st/h7/stm32h7s7l8hxh-pinctrl.dtsi:4036 */
				slew-rate = "very-high-speed"; /* in modules/hal/stm32/dts/st/h7/stm32h7s7l8hxh-pinctrl.dtsi:4037 */
				phandle = < 0x29 >;            /* in zephyr/boards/st/stm32h7s78_dk/stm32h7s78_dk-common.dtsi:241 */
			};

			/* node '/soc/pin-controller@58020000/xspim_p2_clk_pn6' defined in modules/hal/stm32/dts/st/h7/stm32h7s7l8hxh-pinctrl.dtsi:4040 */
			xspim_p2_clk_pn6: xspim_p2_clk_pn6 {
				pinmux = < 0x1ac9 >;           /* in modules/hal/stm32/dts/st/h7/stm32h7s7l8hxh-pinctrl.dtsi:4041 */
				slew-rate = "very-high-speed"; /* in modules/hal/stm32/dts/st/h7/stm32h7s7l8hxh-pinctrl.dtsi:4042 */
				phandle = < 0x24 >;            /* in zephyr/boards/st/stm32h7s78_dk/stm32h7s78_dk-common.dtsi:241 */
			};

			/* node '/soc/pin-controller@58020000/xspim_p2_io4_pn8' defined in modules/hal/stm32/dts/st/h7/stm32h7s7l8hxh-pinctrl.dtsi:4050 */
			xspim_p2_io4_pn8: xspim_p2_io4_pn8 {
				pinmux = < 0x1b09 >;           /* in modules/hal/stm32/dts/st/h7/stm32h7s7l8hxh-pinctrl.dtsi:4051 */
				slew-rate = "very-high-speed"; /* in modules/hal/stm32/dts/st/h7/stm32h7s7l8hxh-pinctrl.dtsi:4052 */
				phandle = < 0x2a >;            /* in zephyr/boards/st/stm32h7s78_dk/stm32h7s78_dk-common.dtsi:241 */
			};

			/* node '/soc/pin-controller@58020000/xspim_p2_io5_pn9' defined in modules/hal/stm32/dts/st/h7/stm32h7s7l8hxh-pinctrl.dtsi:4055 */
			xspim_p2_io5_pn9: xspim_p2_io5_pn9 {
				pinmux = < 0x1b29 >;           /* in modules/hal/stm32/dts/st/h7/stm32h7s7l8hxh-pinctrl.dtsi:4056 */
				slew-rate = "very-high-speed"; /* in modules/hal/stm32/dts/st/h7/stm32h7s7l8hxh-pinctrl.dtsi:4057 */
				phandle = < 0x2b >;            /* in zephyr/boards/st/stm32h7s78_dk/stm32h7s78_dk-common.dtsi:241 */
			};

			/* node '/soc/pin-controller@58020000/xspim_p2_io6_pn10' defined in modules/hal/stm32/dts/st/h7/stm32h7s7l8hxh-pinctrl.dtsi:4060 */
			xspim_p2_io6_pn10: xspim_p2_io6_pn10 {
				pinmux = < 0x1b49 >;           /* in modules/hal/stm32/dts/st/h7/stm32h7s7l8hxh-pinctrl.dtsi:4061 */
				slew-rate = "very-high-speed"; /* in modules/hal/stm32/dts/st/h7/stm32h7s7l8hxh-pinctrl.dtsi:4062 */
				phandle = < 0x2c >;            /* in zephyr/boards/st/stm32h7s78_dk/stm32h7s78_dk-common.dtsi:241 */
			};

			/* node '/soc/pin-controller@58020000/xspim_p2_io7_pn11' defined in modules/hal/stm32/dts/st/h7/stm32h7s7l8hxh-pinctrl.dtsi:4065 */
			xspim_p2_io7_pn11: xspim_p2_io7_pn11 {
				pinmux = < 0x1b69 >;           /* in modules/hal/stm32/dts/st/h7/stm32h7s7l8hxh-pinctrl.dtsi:4066 */
				slew-rate = "very-high-speed"; /* in modules/hal/stm32/dts/st/h7/stm32h7s7l8hxh-pinctrl.dtsi:4067 */
				phandle = < 0x2d >;            /* in zephyr/boards/st/stm32h7s78_dk/stm32h7s78_dk-common.dtsi:241 */
			};

			/* node '/soc/pin-controller@58020000/xspim_p1_ncs1_po0' defined in modules/hal/stm32/dts/st/h7/stm32h7s7l8hxh-pinctrl.dtsi:4075 */
			xspim_p1_ncs1_po0: xspim_p1_ncs1_po0 {
				pinmux = < 0x1c09 >;           /* in modules/hal/stm32/dts/st/h7/stm32h7s7l8hxh-pinctrl.dtsi:4076 */
				slew-rate = "very-high-speed"; /* in modules/hal/stm32/dts/st/h7/stm32h7s7l8hxh-pinctrl.dtsi:4077 */
				phandle = < 0x10 >;            /* in zephyr/boards/st/stm32h7s78_dk/stm32h7s78_dk-common.dtsi:213 */
			};

			/* node '/soc/pin-controller@58020000/xspim_p1_dqs0_po2' defined in modules/hal/stm32/dts/st/h7/stm32h7s7l8hxh-pinctrl.dtsi:4085 */
			xspim_p1_dqs0_po2: xspim_p1_dqs0_po2 {
				pinmux = < 0x1c49 >;           /* in modules/hal/stm32/dts/st/h7/stm32h7s7l8hxh-pinctrl.dtsi:4086 */
				slew-rate = "very-high-speed"; /* in modules/hal/stm32/dts/st/h7/stm32h7s7l8hxh-pinctrl.dtsi:4087 */
				phandle = < 0x11 >;            /* in zephyr/boards/st/stm32h7s78_dk/stm32h7s78_dk-common.dtsi:213 */
			};

			/* node '/soc/pin-controller@58020000/xspim_p1_dqs1_po3' defined in modules/hal/stm32/dts/st/h7/stm32h7s7l8hxh-pinctrl.dtsi:4090 */
			xspim_p1_dqs1_po3: xspim_p1_dqs1_po3 {
				pinmux = < 0x1c69 >;           /* in modules/hal/stm32/dts/st/h7/stm32h7s7l8hxh-pinctrl.dtsi:4091 */
				slew-rate = "very-high-speed"; /* in modules/hal/stm32/dts/st/h7/stm32h7s7l8hxh-pinctrl.dtsi:4092 */
				phandle = < 0x12 >;            /* in zephyr/boards/st/stm32h7s78_dk/stm32h7s78_dk-common.dtsi:213 */
			};

			/* node '/soc/pin-controller@58020000/xspim_p1_clk_po4' defined in modules/hal/stm32/dts/st/h7/stm32h7s7l8hxh-pinctrl.dtsi:4095 */
			xspim_p1_clk_po4: xspim_p1_clk_po4 {
				pinmux = < 0x1c89 >;           /* in modules/hal/stm32/dts/st/h7/stm32h7s7l8hxh-pinctrl.dtsi:4096 */
				slew-rate = "very-high-speed"; /* in modules/hal/stm32/dts/st/h7/stm32h7s7l8hxh-pinctrl.dtsi:4097 */
				phandle = < 0x13 >;            /* in zephyr/boards/st/stm32h7s78_dk/stm32h7s78_dk-common.dtsi:213 */
			};

			/* node '/soc/pin-controller@58020000/xspim_p1_io0_pp0' defined in modules/hal/stm32/dts/st/h7/stm32h7s7l8hxh-pinctrl.dtsi:4105 */
			xspim_p1_io0_pp0: xspim_p1_io0_pp0 {
				pinmux = < 0x1e09 >;           /* in modules/hal/stm32/dts/st/h7/stm32h7s7l8hxh-pinctrl.dtsi:4106 */
				slew-rate = "very-high-speed"; /* in modules/hal/stm32/dts/st/h7/stm32h7s7l8hxh-pinctrl.dtsi:4107 */
				phandle = < 0x14 >;            /* in zephyr/boards/st/stm32h7s78_dk/stm32h7s78_dk-common.dtsi:213 */
			};

			/* node '/soc/pin-controller@58020000/xspim_p1_io1_pp1' defined in modules/hal/stm32/dts/st/h7/stm32h7s7l8hxh-pinctrl.dtsi:4110 */
			xspim_p1_io1_pp1: xspim_p1_io1_pp1 {
				pinmux = < 0x1e29 >;           /* in modules/hal/stm32/dts/st/h7/stm32h7s7l8hxh-pinctrl.dtsi:4111 */
				slew-rate = "very-high-speed"; /* in modules/hal/stm32/dts/st/h7/stm32h7s7l8hxh-pinctrl.dtsi:4112 */
				phandle = < 0x15 >;            /* in zephyr/boards/st/stm32h7s78_dk/stm32h7s78_dk-common.dtsi:213 */
			};

			/* node '/soc/pin-controller@58020000/xspim_p1_io2_pp2' defined in modules/hal/stm32/dts/st/h7/stm32h7s7l8hxh-pinctrl.dtsi:4115 */
			xspim_p1_io2_pp2: xspim_p1_io2_pp2 {
				pinmux = < 0x1e49 >;           /* in modules/hal/stm32/dts/st/h7/stm32h7s7l8hxh-pinctrl.dtsi:4116 */
				slew-rate = "very-high-speed"; /* in modules/hal/stm32/dts/st/h7/stm32h7s7l8hxh-pinctrl.dtsi:4117 */
				phandle = < 0x16 >;            /* in zephyr/boards/st/stm32h7s78_dk/stm32h7s78_dk-common.dtsi:213 */
			};

			/* node '/soc/pin-controller@58020000/xspim_p1_io3_pp3' defined in modules/hal/stm32/dts/st/h7/stm32h7s7l8hxh-pinctrl.dtsi:4120 */
			xspim_p1_io3_pp3: xspim_p1_io3_pp3 {
				pinmux = < 0x1e69 >;           /* in modules/hal/stm32/dts/st/h7/stm32h7s7l8hxh-pinctrl.dtsi:4121 */
				slew-rate = "very-high-speed"; /* in modules/hal/stm32/dts/st/h7/stm32h7s7l8hxh-pinctrl.dtsi:4122 */
				phandle = < 0x17 >;            /* in zephyr/boards/st/stm32h7s78_dk/stm32h7s78_dk-common.dtsi:213 */
			};

			/* node '/soc/pin-controller@58020000/xspim_p1_io4_pp4' defined in modules/hal/stm32/dts/st/h7/stm32h7s7l8hxh-pinctrl.dtsi:4125 */
			xspim_p1_io4_pp4: xspim_p1_io4_pp4 {
				pinmux = < 0x1e89 >;           /* in modules/hal/stm32/dts/st/h7/stm32h7s7l8hxh-pinctrl.dtsi:4126 */
				slew-rate = "very-high-speed"; /* in modules/hal/stm32/dts/st/h7/stm32h7s7l8hxh-pinctrl.dtsi:4127 */
				phandle = < 0x18 >;            /* in zephyr/boards/st/stm32h7s78_dk/stm32h7s78_dk-common.dtsi:213 */
			};

			/* node '/soc/pin-controller@58020000/xspim_p1_io5_pp5' defined in modules/hal/stm32/dts/st/h7/stm32h7s7l8hxh-pinctrl.dtsi:4130 */
			xspim_p1_io5_pp5: xspim_p1_io5_pp5 {
				pinmux = < 0x1ea9 >;           /* in modules/hal/stm32/dts/st/h7/stm32h7s7l8hxh-pinctrl.dtsi:4131 */
				slew-rate = "very-high-speed"; /* in modules/hal/stm32/dts/st/h7/stm32h7s7l8hxh-pinctrl.dtsi:4132 */
				phandle = < 0x19 >;            /* in zephyr/boards/st/stm32h7s78_dk/stm32h7s78_dk-common.dtsi:213 */
			};

			/* node '/soc/pin-controller@58020000/xspim_p1_io6_pp6' defined in modules/hal/stm32/dts/st/h7/stm32h7s7l8hxh-pinctrl.dtsi:4135 */
			xspim_p1_io6_pp6: xspim_p1_io6_pp6 {
				pinmux = < 0x1ec9 >;           /* in modules/hal/stm32/dts/st/h7/stm32h7s7l8hxh-pinctrl.dtsi:4136 */
				slew-rate = "very-high-speed"; /* in modules/hal/stm32/dts/st/h7/stm32h7s7l8hxh-pinctrl.dtsi:4137 */
				phandle = < 0x1a >;            /* in zephyr/boards/st/stm32h7s78_dk/stm32h7s78_dk-common.dtsi:213 */
			};

			/* node '/soc/pin-controller@58020000/xspim_p1_io7_pp7' defined in modules/hal/stm32/dts/st/h7/stm32h7s7l8hxh-pinctrl.dtsi:4140 */
			xspim_p1_io7_pp7: xspim_p1_io7_pp7 {
				pinmux = < 0x1ee9 >;           /* in modules/hal/stm32/dts/st/h7/stm32h7s7l8hxh-pinctrl.dtsi:4141 */
				slew-rate = "very-high-speed"; /* in modules/hal/stm32/dts/st/h7/stm32h7s7l8hxh-pinctrl.dtsi:4142 */
				phandle = < 0x1b >;            /* in zephyr/boards/st/stm32h7s78_dk/stm32h7s78_dk-common.dtsi:213 */
			};

			/* node '/soc/pin-controller@58020000/xspim_p1_io8_pp8' defined in modules/hal/stm32/dts/st/h7/stm32h7s7l8hxh-pinctrl.dtsi:4145 */
			xspim_p1_io8_pp8: xspim_p1_io8_pp8 {
				pinmux = < 0x1f09 >;           /* in modules/hal/stm32/dts/st/h7/stm32h7s7l8hxh-pinctrl.dtsi:4146 */
				slew-rate = "very-high-speed"; /* in modules/hal/stm32/dts/st/h7/stm32h7s7l8hxh-pinctrl.dtsi:4147 */
				phandle = < 0x1c >;            /* in zephyr/boards/st/stm32h7s78_dk/stm32h7s78_dk-common.dtsi:213 */
			};

			/* node '/soc/pin-controller@58020000/xspim_p1_io9_pp9' defined in modules/hal/stm32/dts/st/h7/stm32h7s7l8hxh-pinctrl.dtsi:4150 */
			xspim_p1_io9_pp9: xspim_p1_io9_pp9 {
				pinmux = < 0x1f29 >;           /* in modules/hal/stm32/dts/st/h7/stm32h7s7l8hxh-pinctrl.dtsi:4151 */
				slew-rate = "very-high-speed"; /* in modules/hal/stm32/dts/st/h7/stm32h7s7l8hxh-pinctrl.dtsi:4152 */
				phandle = < 0x1d >;            /* in zephyr/boards/st/stm32h7s78_dk/stm32h7s78_dk-common.dtsi:213 */
			};

			/* node '/soc/pin-controller@58020000/xspim_p1_io10_pp10' defined in modules/hal/stm32/dts/st/h7/stm32h7s7l8hxh-pinctrl.dtsi:4155 */
			xspim_p1_io10_pp10: xspim_p1_io10_pp10 {
				pinmux = < 0x1f49 >;           /* in modules/hal/stm32/dts/st/h7/stm32h7s7l8hxh-pinctrl.dtsi:4156 */
				slew-rate = "very-high-speed"; /* in modules/hal/stm32/dts/st/h7/stm32h7s7l8hxh-pinctrl.dtsi:4157 */
				phandle = < 0x1e >;            /* in zephyr/boards/st/stm32h7s78_dk/stm32h7s78_dk-common.dtsi:213 */
			};

			/* node '/soc/pin-controller@58020000/xspim_p1_io11_pp11' defined in modules/hal/stm32/dts/st/h7/stm32h7s7l8hxh-pinctrl.dtsi:4160 */
			xspim_p1_io11_pp11: xspim_p1_io11_pp11 {
				pinmux = < 0x1f69 >;           /* in modules/hal/stm32/dts/st/h7/stm32h7s7l8hxh-pinctrl.dtsi:4161 */
				slew-rate = "very-high-speed"; /* in modules/hal/stm32/dts/st/h7/stm32h7s7l8hxh-pinctrl.dtsi:4162 */
				phandle = < 0x1f >;            /* in zephyr/boards/st/stm32h7s78_dk/stm32h7s78_dk-common.dtsi:213 */
			};

			/* node '/soc/pin-controller@58020000/xspim_p1_io12_pp12' defined in modules/hal/stm32/dts/st/h7/stm32h7s7l8hxh-pinctrl.dtsi:4165 */
			xspim_p1_io12_pp12: xspim_p1_io12_pp12 {
				pinmux = < 0x1f89 >;           /* in modules/hal/stm32/dts/st/h7/stm32h7s7l8hxh-pinctrl.dtsi:4166 */
				slew-rate = "very-high-speed"; /* in modules/hal/stm32/dts/st/h7/stm32h7s7l8hxh-pinctrl.dtsi:4167 */
				phandle = < 0x20 >;            /* in zephyr/boards/st/stm32h7s78_dk/stm32h7s78_dk-common.dtsi:213 */
			};

			/* node '/soc/pin-controller@58020000/xspim_p1_io13_pp13' defined in modules/hal/stm32/dts/st/h7/stm32h7s7l8hxh-pinctrl.dtsi:4170 */
			xspim_p1_io13_pp13: xspim_p1_io13_pp13 {
				pinmux = < 0x1fa9 >;           /* in modules/hal/stm32/dts/st/h7/stm32h7s7l8hxh-pinctrl.dtsi:4171 */
				slew-rate = "very-high-speed"; /* in modules/hal/stm32/dts/st/h7/stm32h7s7l8hxh-pinctrl.dtsi:4172 */
				phandle = < 0x21 >;            /* in zephyr/boards/st/stm32h7s78_dk/stm32h7s78_dk-common.dtsi:213 */
			};

			/* node '/soc/pin-controller@58020000/xspim_p1_io14_pp14' defined in modules/hal/stm32/dts/st/h7/stm32h7s7l8hxh-pinctrl.dtsi:4175 */
			xspim_p1_io14_pp14: xspim_p1_io14_pp14 {
				pinmux = < 0x1fc9 >;           /* in modules/hal/stm32/dts/st/h7/stm32h7s7l8hxh-pinctrl.dtsi:4176 */
				slew-rate = "very-high-speed"; /* in modules/hal/stm32/dts/st/h7/stm32h7s7l8hxh-pinctrl.dtsi:4177 */
				phandle = < 0x22 >;            /* in zephyr/boards/st/stm32h7s78_dk/stm32h7s78_dk-common.dtsi:213 */
			};

			/* node '/soc/pin-controller@58020000/xspim_p1_io15_pp15' defined in modules/hal/stm32/dts/st/h7/stm32h7s7l8hxh-pinctrl.dtsi:4180 */
			xspim_p1_io15_pp15: xspim_p1_io15_pp15 {
				pinmux = < 0x1fe9 >;           /* in modules/hal/stm32/dts/st/h7/stm32h7s7l8hxh-pinctrl.dtsi:4181 */
				slew-rate = "very-high-speed"; /* in modules/hal/stm32/dts/st/h7/stm32h7s7l8hxh-pinctrl.dtsi:4182 */
				phandle = < 0x23 >;            /* in zephyr/boards/st/stm32h7s78_dk/stm32h7s78_dk-common.dtsi:213 */
			};
		};

		/* node '/soc/serial@42001000' defined in zephyr/dts/arm/st/h7rs/stm32h7rs.dtsi:341 */
		usart1: serial@42001000 {
			compatible = "st,stm32-usart",
			             "st,stm32-uart";  /* in zephyr/dts/arm/st/h7rs/stm32h7rs.dtsi:342 */
			reg = < 0x42001000 0x400 >;    /* in zephyr/dts/arm/st/h7rs/stm32h7rs.dtsi:343 */
			clocks = < &rcc 0x150 0x10 >;  /* in zephyr/dts/arm/st/h7rs/stm32h7rs.dtsi:344 */
			resets = < &rctl 0x1304 >;     /* in zephyr/dts/arm/st/h7rs/stm32h7rs.dtsi:345 */
			interrupts = < 0x52 0x0 >;     /* in zephyr/dts/arm/st/h7rs/stm32h7rs.dtsi:346 */
			status = "disabled";           /* in zephyr/dts/arm/st/h7rs/stm32h7rs.dtsi:347 */
		};

		/* node '/soc/serial@40004400' defined in zephyr/dts/arm/st/h7rs/stm32h7rs.dtsi:350 */
		usart2: serial@40004400 {
			compatible = "st,stm32-usart",
			             "st,stm32-uart";    /* in zephyr/dts/arm/st/h7rs/stm32h7rs.dtsi:351 */
			reg = < 0x40004400 0x400 >;      /* in zephyr/dts/arm/st/h7rs/stm32h7rs.dtsi:352 */
			clocks = < &rcc 0x148 0x20000 >; /* in zephyr/dts/arm/st/h7rs/stm32h7rs.dtsi:353 */
			resets = < &rctl 0x1211 >;       /* in zephyr/dts/arm/st/h7rs/stm32h7rs.dtsi:354 */
			interrupts = < 0x53 0x0 >;       /* in zephyr/dts/arm/st/h7rs/stm32h7rs.dtsi:355 */
			status = "disabled";             /* in zephyr/dts/arm/st/h7rs/stm32h7rs.dtsi:356 */
		};

		/* node '/soc/serial@40004800' defined in zephyr/dts/arm/st/h7rs/stm32h7rs.dtsi:359 */
		usart3: serial@40004800 {
			compatible = "st,stm32-usart",
			             "st,stm32-uart";    /* in zephyr/dts/arm/st/h7rs/stm32h7rs.dtsi:360 */
			reg = < 0x40004800 0x400 >;      /* in zephyr/dts/arm/st/h7rs/stm32h7rs.dtsi:361 */
			clocks = < &rcc 0x148 0x40000 >; /* in zephyr/dts/arm/st/h7rs/stm32h7rs.dtsi:362 */
			resets = < &rctl 0x1212 >;       /* in zephyr/dts/arm/st/h7rs/stm32h7rs.dtsi:363 */
			interrupts = < 0x54 0x0 >;       /* in zephyr/dts/arm/st/h7rs/stm32h7rs.dtsi:364 */
			status = "disabled";             /* in zephyr/dts/arm/st/h7rs/stm32h7rs.dtsi:365 */
		};

		/* node '/soc/serial@40004c00' defined in zephyr/dts/arm/st/h7rs/stm32h7rs.dtsi:368 */
		uart4: serial@40004c00 {
			compatible = "st,stm32-uart";                /* in zephyr/dts/arm/st/h7rs/stm32h7rs.dtsi:369 */
			reg = < 0x40004c00 0x400 >;                  /* in zephyr/dts/arm/st/h7rs/stm32h7rs.dtsi:370 */
			clocks = < &rcc 0x148 0x80000 >;             /* in zephyr/dts/arm/st/h7rs/stm32h7rs.dtsi:371 */
			resets = < &rctl 0x1213 >;                   /* in zephyr/dts/arm/st/h7rs/stm32h7rs.dtsi:372 */
			interrupts = < 0x55 0x0 >;                   /* in zephyr/dts/arm/st/h7rs/stm32h7rs.dtsi:373 */
			pinctrl-0 = < &uart4_tx_pd1 &uart4_rx_pd0 >; /* in zephyr/boards/st/stm32h7s78_dk/stm32h7s78_dk-common.dtsi:129 */
			pinctrl-names = "default";                   /* in zephyr/boards/st/stm32h7s78_dk/stm32h7s78_dk-common.dtsi:130 */
			current-speed = < 0x1c200 >;                 /* in zephyr/boards/st/stm32h7s78_dk/stm32h7s78_dk-common.dtsi:131 */
			status = "okay";                             /* in zephyr/boards/st/stm32h7s78_dk/stm32h7s78_dk-common.dtsi:132 */
		};

		/* node '/soc/serial@40005000' defined in zephyr/dts/arm/st/h7rs/stm32h7rs.dtsi:377 */
		uart5: serial@40005000 {
			compatible = "st,stm32-uart";     /* in zephyr/dts/arm/st/h7rs/stm32h7rs.dtsi:378 */
			reg = < 0x40005000 0x400 >;       /* in zephyr/dts/arm/st/h7rs/stm32h7rs.dtsi:379 */
			clocks = < &rcc 0x148 0x100000 >; /* in zephyr/dts/arm/st/h7rs/stm32h7rs.dtsi:380 */
			resets = < &rctl 0x1214 >;        /* in zephyr/dts/arm/st/h7rs/stm32h7rs.dtsi:381 */
			interrupts = < 0x56 0x0 >;        /* in zephyr/dts/arm/st/h7rs/stm32h7rs.dtsi:382 */
			status = "disabled";              /* in zephyr/dts/arm/st/h7rs/stm32h7rs.dtsi:383 */
		};

		/* node '/soc/serial@40007800' defined in zephyr/dts/arm/st/h7rs/stm32h7rs.dtsi:386 */
		uart7: serial@40007800 {
			compatible = "st,stm32-uart";                /* in zephyr/dts/arm/st/h7rs/stm32h7rs.dtsi:387 */
			reg = < 0x40007800 0x400 >;                  /* in zephyr/dts/arm/st/h7rs/stm32h7rs.dtsi:388 */
			clocks = < &rcc 0x148 0x40000000 >;          /* in zephyr/dts/arm/st/h7rs/stm32h7rs.dtsi:389 */
			resets = < &rctl 0x121e >;                   /* in zephyr/dts/arm/st/h7rs/stm32h7rs.dtsi:390 */
			interrupts = < 0x57 0x0 >;                   /* in zephyr/dts/arm/st/h7rs/stm32h7rs.dtsi:391 */
			pinctrl-0 = < &uart7_tx_pe8 &uart7_rx_pe7 >; /* in zephyr/boards/st/stm32h7s78_dk/stm32h7s78_dk-common.dtsi:136 */
			pinctrl-names = "default";                   /* in zephyr/boards/st/stm32h7s78_dk/stm32h7s78_dk-common.dtsi:137 */
			current-speed = < 0x1c200 >;                 /* in zephyr/boards/st/stm32h7s78_dk/stm32h7s78_dk-common.dtsi:138 */
			status = "okay";                             /* in zephyr/boards/st/stm32h7s78_dk/stm32h7s78_dk-common.dtsi:139 */
		};

		/* node '/soc/serial@40007c00' defined in zephyr/dts/arm/st/h7rs/stm32h7rs.dtsi:395 */
		uart8: serial@40007c00 {
			compatible = "st,stm32-uart";       /* in zephyr/dts/arm/st/h7rs/stm32h7rs.dtsi:396 */
			reg = < 0x40007c00 0x400 >;         /* in zephyr/dts/arm/st/h7rs/stm32h7rs.dtsi:397 */
			clocks = < &rcc 0x148 0x80000000 >; /* in zephyr/dts/arm/st/h7rs/stm32h7rs.dtsi:398 */
			resets = < &rctl 0x121f >;          /* in zephyr/dts/arm/st/h7rs/stm32h7rs.dtsi:399 */
			interrupts = < 0x58 0x0 >;          /* in zephyr/dts/arm/st/h7rs/stm32h7rs.dtsi:400 */
			status = "disabled";                /* in zephyr/dts/arm/st/h7rs/stm32h7rs.dtsi:401 */
		};

		/* node '/soc/serial@58000c00' defined in zephyr/dts/arm/st/h7rs/stm32h7rs.dtsi:404 */
		lpuart1: serial@58000c00 {
			compatible = "st,stm32-lpuart",
			             "st,stm32-uart";   /* in zephyr/dts/arm/st/h7rs/stm32h7rs.dtsi:405 */
			reg = < 0x58000c00 0x400 >;     /* in zephyr/dts/arm/st/h7rs/stm32h7rs.dtsi:406 */
			clocks = < &rcc 0x154 0x8 >;    /* in zephyr/dts/arm/st/h7rs/stm32h7rs.dtsi:407 */
			resets = < &rctl 0x1383 >;      /* in zephyr/dts/arm/st/h7rs/stm32h7rs.dtsi:408 */
			interrupts = < 0x83 0x0 >;      /* in zephyr/dts/arm/st/h7rs/stm32h7rs.dtsi:409 */
			status = "disabled";            /* in zephyr/dts/arm/st/h7rs/stm32h7rs.dtsi:410 */
		};

		/* node '/soc/i2c@40005400' defined in zephyr/dts/arm/st/h7rs/stm32h7rs.dtsi:413 */
		i2c1: arduino_i2c: i2c@40005400 {
			compatible = "st,stm32-i2c-v2";              /* in zephyr/dts/arm/st/h7rs/stm32h7rs.dtsi:414 */
			clock-frequency = < 0x186a0 >;               /* in zephyr/dts/arm/st/h7rs/stm32h7rs.dtsi:415 */
			#address-cells = < 0x1 >;                    /* in zephyr/dts/arm/st/h7rs/stm32h7rs.dtsi:416 */
			#size-cells = < 0x0 >;                       /* in zephyr/dts/arm/st/h7rs/stm32h7rs.dtsi:417 */
			reg = < 0x40005400 0x400 >;                  /* in zephyr/dts/arm/st/h7rs/stm32h7rs.dtsi:418 */
			clocks = < &rcc 0x148 0x200000 >;            /* in zephyr/dts/arm/st/h7rs/stm32h7rs.dtsi:419 */
			interrupts = < 0x4c 0x0 >,
			             < 0x4d 0x0 >;                   /* in zephyr/dts/arm/st/h7rs/stm32h7rs.dtsi:420 */
			interrupt-names = "event",
			                  "error";                   /* in zephyr/dts/arm/st/h7rs/stm32h7rs.dtsi:421 */
			pinctrl-0 = < &i2c1_scl_pb6 &i2c1_sda_pb9 >; /* in zephyr/boards/st/stm32h7s78_dk/stm32h7s78_dk-common.dtsi:200 */
			pinctrl-names = "default";                   /* in zephyr/boards/st/stm32h7s78_dk/stm32h7s78_dk-common.dtsi:201 */
			status = "okay";                             /* in zephyr/boards/st/stm32h7s78_dk/stm32h7s78_dk-common.dtsi:202 */

			/* node '/soc/i2c@40005400/gt911@5d' defined in zephyr/boards/st/stm32h7s78_dk/stm32h7s78_dk-common.dtsi:204 */
			display_ctp: gt911@5d {
				compatible = "goodix,gt911";     /* in zephyr/boards/st/stm32h7s78_dk/stm32h7s78_dk-common.dtsi:205 */
				reg = < 0x5d >;                  /* in zephyr/boards/st/stm32h7s78_dk/stm32h7s78_dk-common.dtsi:206 */
				irq-gpios = < &gpioe 0x3 0x20 >; /* in zephyr/boards/st/stm32h7s78_dk/stm32h7s78_dk-common.dtsi:207 */
				status = "okay";                 /* in zephyr/boards/st/stm32h7s78_dk/stm32h7s78_dk-common.dtsi:208 */
			};
		};

		/* node '/soc/i2c@40005800' defined in zephyr/dts/arm/st/h7rs/stm32h7rs.dtsi:425 */
		i2c2: i2c@40005800 {
			compatible = "st,stm32-i2c-v2";   /* in zephyr/dts/arm/st/h7rs/stm32h7rs.dtsi:426 */
			clock-frequency = < 0x186a0 >;    /* in zephyr/dts/arm/st/h7rs/stm32h7rs.dtsi:427 */
			#address-cells = < 0x1 >;         /* in zephyr/dts/arm/st/h7rs/stm32h7rs.dtsi:428 */
			#size-cells = < 0x0 >;            /* in zephyr/dts/arm/st/h7rs/stm32h7rs.dtsi:429 */
			reg = < 0x40005800 0x400 >;       /* in zephyr/dts/arm/st/h7rs/stm32h7rs.dtsi:430 */
			clocks = < &rcc 0x148 0x400000 >; /* in zephyr/dts/arm/st/h7rs/stm32h7rs.dtsi:431 */
			interrupts = < 0x4e 0x0 >,
			             < 0x4f 0x0 >;        /* in zephyr/dts/arm/st/h7rs/stm32h7rs.dtsi:432 */
			interrupt-names = "event",
			                  "error";        /* in zephyr/dts/arm/st/h7rs/stm32h7rs.dtsi:433 */
			status = "disabled";              /* in zephyr/dts/arm/st/h7rs/stm32h7rs.dtsi:434 */
		};

		/* node '/soc/i2c@40005c00' defined in zephyr/dts/arm/st/h7rs/stm32h7rs.dtsi:437 */
		i2c3: i2c@40005c00 {
			compatible = "st,stm32-i2c-v2";   /* in zephyr/dts/arm/st/h7rs/stm32h7rs.dtsi:438 */
			clock-frequency = < 0x186a0 >;    /* in zephyr/dts/arm/st/h7rs/stm32h7rs.dtsi:439 */
			#address-cells = < 0x1 >;         /* in zephyr/dts/arm/st/h7rs/stm32h7rs.dtsi:440 */
			#size-cells = < 0x0 >;            /* in zephyr/dts/arm/st/h7rs/stm32h7rs.dtsi:441 */
			reg = < 0x40005c00 0x400 >;       /* in zephyr/dts/arm/st/h7rs/stm32h7rs.dtsi:442 */
			clocks = < &rcc 0x148 0x800000 >; /* in zephyr/dts/arm/st/h7rs/stm32h7rs.dtsi:443 */
			interrupts = < 0x50 0x0 >,
			             < 0x51 0x0 >;        /* in zephyr/dts/arm/st/h7rs/stm32h7rs.dtsi:444 */
			interrupt-names = "event",
			                  "error";        /* in zephyr/dts/arm/st/h7rs/stm32h7rs.dtsi:445 */
			status = "disabled";              /* in zephyr/dts/arm/st/h7rs/stm32h7rs.dtsi:446 */
		};

		/* node '/soc/spi@42003000' defined in zephyr/dts/arm/st/h7rs/stm32h7rs.dtsi:449 */
		spi1: spi@42003000 {
			compatible = "st,stm32h7-spi",
			             "st,stm32-spi-fifo",
			             "st,stm32-spi";      /* in zephyr/dts/arm/st/h7rs/stm32h7rs.dtsi:450 */
			#address-cells = < 0x1 >;         /* in zephyr/dts/arm/st/h7rs/stm32h7rs.dtsi:451 */
			#size-cells = < 0x0 >;            /* in zephyr/dts/arm/st/h7rs/stm32h7rs.dtsi:452 */
			reg = < 0x42003000 0x400 >;       /* in zephyr/dts/arm/st/h7rs/stm32h7rs.dtsi:453 */
			clocks = < &rcc 0x150 0x1000 >,
			         < &rcc 0x9 0x480054 >;   /* in zephyr/dts/arm/st/h7rs/stm32h7rs.dtsi:454 */
			interrupts = < 0x3a 0x0 >;        /* in zephyr/dts/arm/st/h7rs/stm32h7rs.dtsi:456 */
			status = "disabled";              /* in zephyr/dts/arm/st/h7rs/stm32h7rs.dtsi:457 */
		};

		/* node '/soc/spi@40003800' defined in zephyr/dts/arm/st/h7rs/stm32h7rs.dtsi:460 */
		spi2: spi@40003800 {
			compatible = "st,stm32h7-spi",
			             "st,stm32-spi-fifo",
			             "st,stm32-spi";      /* in zephyr/dts/arm/st/h7rs/stm32h7rs.dtsi:461 */
			#address-cells = < 0x1 >;         /* in zephyr/dts/arm/st/h7rs/stm32h7rs.dtsi:462 */
			#size-cells = < 0x0 >;            /* in zephyr/dts/arm/st/h7rs/stm32h7rs.dtsi:463 */
			reg = < 0x40003800 0x400 >;       /* in zephyr/dts/arm/st/h7rs/stm32h7rs.dtsi:464 */
			clocks = < &rcc 0x148 0x4000 >,
			         < &rcc 0x9 0x440050 >;   /* in zephyr/dts/arm/st/h7rs/stm32h7rs.dtsi:465 */
			interrupts = < 0x3b 0x0 >;        /* in zephyr/dts/arm/st/h7rs/stm32h7rs.dtsi:467 */
			status = "disabled";              /* in zephyr/dts/arm/st/h7rs/stm32h7rs.dtsi:468 */
		};

		/* node '/soc/spi@40003c00' defined in zephyr/dts/arm/st/h7rs/stm32h7rs.dtsi:471 */
		spi3: spi@40003c00 {
			compatible = "st,stm32h7-spi",
			             "st,stm32-spi-fifo",
			             "st,stm32-spi";      /* in zephyr/dts/arm/st/h7rs/stm32h7rs.dtsi:472 */
			#address-cells = < 0x1 >;         /* in zephyr/dts/arm/st/h7rs/stm32h7rs.dtsi:473 */
			#size-cells = < 0x0 >;            /* in zephyr/dts/arm/st/h7rs/stm32h7rs.dtsi:474 */
			reg = < 0x40003c00 0x400 >;       /* in zephyr/dts/arm/st/h7rs/stm32h7rs.dtsi:475 */
			clocks = < &rcc 0x148 0x8000 >,
			         < &rcc 0x9 0x440050 >;   /* in zephyr/dts/arm/st/h7rs/stm32h7rs.dtsi:476 */
			interrupts = < 0x3c 0x0 >;        /* in zephyr/dts/arm/st/h7rs/stm32h7rs.dtsi:478 */
			status = "disabled";              /* in zephyr/dts/arm/st/h7rs/stm32h7rs.dtsi:479 */
		};

		/* node '/soc/spi@42003400' defined in zephyr/dts/arm/st/h7rs/stm32h7rs.dtsi:482 */
		spi4: arduino_spi: spi@42003400 {
			compatible = "st,stm32h7-spi",
			             "st,stm32-spi-fifo",
			             "st,stm32-spi";                                                  /* in zephyr/dts/arm/st/h7rs/stm32h7rs.dtsi:483 */
			#address-cells = < 0x1 >;                                                     /* in zephyr/dts/arm/st/h7rs/stm32h7rs.dtsi:484 */
			#size-cells = < 0x0 >;                                                        /* in zephyr/dts/arm/st/h7rs/stm32h7rs.dtsi:485 */
			reg = < 0x42003400 0x400 >;                                                   /* in zephyr/dts/arm/st/h7rs/stm32h7rs.dtsi:486 */
			clocks = < &rcc 0x150 0x2000 >;                                               /* in zephyr/dts/arm/st/h7rs/stm32h7rs.dtsi:487 */
			interrupts = < 0x3d 0x0 >;                                                    /* in zephyr/dts/arm/st/h7rs/stm32h7rs.dtsi:488 */
			pinctrl-0 = < &spi4_nss_pe4 &spi4_sck_pe12 &spi4_miso_pe13 &spi4_mosi_pe14 >; /* in zephyr/boards/st/stm32h7s78_dk/stm32h7s78_dk-common.dtsi:193 */
			pinctrl-names = "default";                                                    /* in zephyr/boards/st/stm32h7s78_dk/stm32h7s78_dk-common.dtsi:195 */
			status = "okay";                                                              /* in zephyr/boards/st/stm32h7s78_dk/stm32h7s78_dk-common.dtsi:196 */
		};

		/* node '/soc/spi@42005000' defined in zephyr/dts/arm/st/h7rs/stm32h7rs.dtsi:492 */
		spi5: spi@42005000 {
			compatible = "st,stm32h7-spi",
			             "st,stm32-spi-fifo",
			             "st,stm32-spi";      /* in zephyr/dts/arm/st/h7rs/stm32h7rs.dtsi:493 */
			#address-cells = < 0x1 >;         /* in zephyr/dts/arm/st/h7rs/stm32h7rs.dtsi:494 */
			#size-cells = < 0x0 >;            /* in zephyr/dts/arm/st/h7rs/stm32h7rs.dtsi:495 */
			reg = < 0x42005000 0x400 >;       /* in zephyr/dts/arm/st/h7rs/stm32h7rs.dtsi:496 */
			clocks = < &rcc 0x150 0x100000 >; /* in zephyr/dts/arm/st/h7rs/stm32h7rs.dtsi:497 */
			interrupts = < 0x3e 0x0 >;        /* in zephyr/dts/arm/st/h7rs/stm32h7rs.dtsi:498 */
			status = "disabled";              /* in zephyr/dts/arm/st/h7rs/stm32h7rs.dtsi:499 */
		};

		/* node '/soc/i2s@40013000' defined in zephyr/dts/arm/st/h7rs/stm32h7rs.dtsi:502 */
		i2s1: i2s@40013000 {
			compatible = "st,stm32h7-i2s",
			             "st,stm32-i2s";    /* in zephyr/dts/arm/st/h7rs/stm32h7rs.dtsi:503 */
			#address-cells = < 0x1 >;       /* in zephyr/dts/arm/st/h7rs/stm32h7rs.dtsi:504 */
			#size-cells = < 0x0 >;          /* in zephyr/dts/arm/st/h7rs/stm32h7rs.dtsi:505 */
			reg = < 0x40013000 0x400 >;     /* in zephyr/dts/arm/st/h7rs/stm32h7rs.dtsi:506 */
			clocks = < &rcc 0x150 0x1000 >,
			         < &rcc 0x9 0x480054 >; /* in zephyr/dts/arm/st/h7rs/stm32h7rs.dtsi:507 */
			interrupts = < 0x23 0x3 >;      /* in zephyr/dts/arm/st/h7rs/stm32h7rs.dtsi:509 */
			status = "disabled";            /* in zephyr/dts/arm/st/h7rs/stm32h7rs.dtsi:510 */
		};

		/* node '/soc/can@4000a000' defined in zephyr/dts/arm/st/h7rs/stm32h7rs.dtsi:513 */
		fdcan1: can@4000a000 {
			compatible = "st,stm32-fdcan";                         /* in zephyr/dts/arm/st/h7rs/stm32h7rs.dtsi:514 */
			reg = < 0x4000a000 0x400 >,
			      < 0x4000ac00 0x350 >;                            /* in zephyr/dts/arm/st/h7rs/stm32h7rs.dtsi:515 */
			reg-names = "m_can",
			            "message_ram";                             /* in zephyr/dts/arm/st/h7rs/stm32h7rs.dtsi:516 */
			clocks = < &rcc 0x14c 0x100 >,
			         < &rcc 0x4 0x360050 >;                        /* in zephyr/dts/arm/st/h7rs/stm32h7rs.dtsi:518 */
			interrupts = < 0x98 0x0 >,
			             < 0x99 0x0 >;                             /* in zephyr/dts/arm/st/h7rs/stm32h7rs.dtsi:520 */
			interrupt-names = "int0",
			                  "int1";                              /* in zephyr/dts/arm/st/h7rs/stm32h7rs.dtsi:521 */
			bosch,mram-cfg = < 0x0 0x1c 0x8 0x3 0x3 0x0 0x3 0x3 >; /* in zephyr/dts/arm/st/h7rs/stm32h7rs.dtsi:522 */
			status = "disabled";                                   /* in zephyr/dts/arm/st/h7rs/stm32h7rs.dtsi:523 */
		};

		/* node '/soc/can@4000a400' defined in zephyr/dts/arm/st/h7rs/stm32h7rs.dtsi:526 */
		fdcan2: can@4000a400 {
			compatible = "st,stm32-fdcan";                           /* in zephyr/dts/arm/st/h7rs/stm32h7rs.dtsi:527 */
			reg = < 0x4000a400 0x400 >,
			      < 0x4000ac00 0x6a0 >;                              /* in zephyr/dts/arm/st/h7rs/stm32h7rs.dtsi:528 */
			reg-names = "m_can",
			            "message_ram";                               /* in zephyr/dts/arm/st/h7rs/stm32h7rs.dtsi:529 */
			clocks = < &rcc 0x14c 0x100 >,
			         < &rcc 0x4 0x360050 >;                          /* in zephyr/dts/arm/st/h7rs/stm32h7rs.dtsi:531 */
			interrupts = < 0x9a 0x0 >,
			             < 0x9b 0x0 >;                               /* in zephyr/dts/arm/st/h7rs/stm32h7rs.dtsi:533 */
			interrupt-names = "int0",
			                  "int1";                                /* in zephyr/dts/arm/st/h7rs/stm32h7rs.dtsi:534 */
			bosch,mram-cfg = < 0x350 0x1c 0x8 0x3 0x3 0x0 0x3 0x3 >; /* in zephyr/dts/arm/st/h7rs/stm32h7rs.dtsi:535 */
			status = "disabled";                                     /* in zephyr/dts/arm/st/h7rs/stm32h7rs.dtsi:536 */
		};

		/* node '/soc/spi@52005000' defined in zephyr/dts/arm/st/h7rs/stm32h7rs.dtsi:539 */
		xspi1: spi@52005000 {
			compatible = "st,stm32-xspi";                                                                                        /* in zephyr/dts/arm/st/h7rs/stm32h7rs.dtsi:540 */
			reg = < 0x52005000 0x1000 >,
			      < 0x90000000 0x10000000 >;                                                                                     /* in zephyr/dts/arm/st/h7rs/stm32h7rs.dtsi:541 */
			interrupts = < 0x69 0x0 >;                                                                                           /* in zephyr/dts/arm/st/h7rs/stm32h7rs.dtsi:542 */
			clock-names = "xspix";                                                                                               /* in zephyr/dts/arm/st/h7rs/stm32h7rs.dtsi:543 */
			clocks = < &rcc 0x134 0x20 >;                                                                                        /* in zephyr/dts/arm/st/h7rs/stm32h7rs.dtsi:544 */
			#address-cells = < 0x1 >;                                                                                            /* in zephyr/dts/arm/st/h7rs/stm32h7rs.dtsi:545 */
			#size-cells = < 0x0 >;                                                                                               /* in zephyr/dts/arm/st/h7rs/stm32h7rs.dtsi:546 */
			pinctrl-0 = < &xspim_p1_ncs1_po0 &xspim_p1_dqs0_po2 &xspim_p1_dqs1_po3 &xspim_p1_clk_po4 &xspim_p1_io0_pp0
			              &xspim_p1_io1_pp1 &xspim_p1_io2_pp2 &xspim_p1_io3_pp3 &xspim_p1_io4_pp4 &xspim_p1_io5_pp5
			              &xspim_p1_io6_pp6 &xspim_p1_io7_pp7 &xspim_p1_io8_pp8 &xspim_p1_io9_pp9 &xspim_p1_io10_pp10
			              &xspim_p1_io11_pp11 &xspim_p1_io12_pp12 &xspim_p1_io13_pp13 &xspim_p1_io14_pp14 &xspim_p1_io15_pp15 >; /* in zephyr/boards/st/stm32h7s78_dk/stm32h7s78_dk-common.dtsi:213 */
			pinctrl-names = "default";                                                                                           /* in zephyr/boards/st/stm32h7s78_dk/stm32h7s78_dk-common.dtsi:222 */
			status = "okay";                                                                                                     /* in zephyr/boards/st/stm32h7s78_dk/stm32h7s78_dk-common.dtsi:223 */

			/* node '/soc/spi@52005000/aps256xxn-obr@0' defined in zephyr/boards/st/stm32h7s78_dk/stm32h7s78_dk-common.dtsi:225 */
			memc: aps256xxn-obr@0 {
				compatible = "st,stm32-xspi-psram"; /* in zephyr/boards/st/stm32h7s78_dk/stm32h7s78_dk-common.dtsi:226 */
				reg = < 0x0 >;                      /* in zephyr/boards/st/stm32h7s78_dk/stm32h7s78_dk-common.dtsi:227 */
				size = < 0x10000000 >;              /* in zephyr/boards/st/stm32h7s78_dk/stm32h7s78_dk-common.dtsi:228 */
				max-frequency = < 0xbebc200 >;      /* in zephyr/boards/st/stm32h7s78_dk/stm32h7s78_dk-common.dtsi:229 */
				fixed-latency;                      /* in zephyr/boards/st/stm32h7s78_dk/stm32h7s78_dk-common.dtsi:230 */
				io-x16-mode;                        /* in zephyr/boards/st/stm32h7s78_dk/stm32h7s78_dk-common.dtsi:231 */
				read-latency = < 0x4 >;             /* in zephyr/boards/st/stm32h7s78_dk/stm32h7s78_dk-common.dtsi:232 */
				write-latency = < 0x1 >;            /* in zephyr/boards/st/stm32h7s78_dk/stm32h7s78_dk-common.dtsi:233 */
				burst-length = < 0x0 >;             /* in zephyr/boards/st/stm32h7s78_dk/stm32h7s78_dk-common.dtsi:234 */
				st,csbound = < 0xb >;               /* in zephyr/boards/st/stm32h7s78_dk/stm32h7s78_dk-common.dtsi:235 */
				status = "okay";                    /* in zephyr/boards/st/stm32h7s78_dk/stm32h7s78_dk-common.dtsi:236 */
			};
		};

		/* node '/soc/spi@5200a000' defined in zephyr/dts/arm/st/h7rs/stm32h7rs.dtsi:550 */
		xspi2: spi@5200a000 {
			compatible = "st,stm32-xspi";                                                                             /* in zephyr/dts/arm/st/h7rs/stm32h7rs.dtsi:551 */
			reg = < 0x5200a000 0x1000 >,
			      < 0x70000000 0x10000000 >;                                                                          /* in zephyr/dts/arm/st/h7rs/stm32h7rs.dtsi:552 */
			interrupts = < 0x6a 0x0 >;                                                                                /* in zephyr/dts/arm/st/h7rs/stm32h7rs.dtsi:553 */
			clock-names = "xspix";                                                                                    /* in zephyr/dts/arm/st/h7rs/stm32h7rs.dtsi:554 */
			clocks = < &rcc 0x134 0x1000 >;                                                                           /* in zephyr/dts/arm/st/h7rs/stm32h7rs.dtsi:555 */
			#address-cells = < 0x1 >;                                                                                 /* in zephyr/dts/arm/st/h7rs/stm32h7rs.dtsi:556 */
			#size-cells = < 0x0 >;                                                                                    /* in zephyr/dts/arm/st/h7rs/stm32h7rs.dtsi:557 */
			pinctrl-0 = < &xspim_p2_clk_pn6 &xspim_p2_ncs1_pn1 &xspim_p2_io0_pn2 &xspim_p2_io1_pn3 &xspim_p2_io2_pn4
			              &xspim_p2_io3_pn5 &xspim_p2_io4_pn8 &xspim_p2_io5_pn9 &xspim_p2_io6_pn10 &xspim_p2_io7_pn11
			              &xspim_p2_dqs0_pn0 >;                                                                       /* in zephyr/boards/st/stm32h7s78_dk/stm32h7s78_dk-common.dtsi:241 */
			pinctrl-names = "default";                                                                                /* in zephyr/boards/st/stm32h7s78_dk/stm32h7s78_dk-common.dtsi:247 */
			status = "okay";                                                                                          /* in zephyr/boards/st/stm32h7s78_dk/stm32h7s78_dk-common.dtsi:249 */

			/* node '/soc/spi@5200a000/xspi-nor-flash@0' defined in zephyr/boards/st/stm32h7s78_dk/stm32h7s78_dk-common.dtsi:251 */
			ext_flash_ctrl: xspi-nor-flash@0 {
				compatible = "st,stm32-xspi-nor";      /* in zephyr/boards/st/stm32h7s78_dk/stm32h7s78_dk-common.dtsi:252 */
				reg = < 0x0 >;                         /* in zephyr/boards/st/stm32h7s78_dk/stm32h7s78_dk-common.dtsi:253 */
				size = < 0x40000000 >;                 /* in zephyr/boards/st/stm32h7s78_dk/stm32h7s78_dk-common.dtsi:254 */
				ospi-max-frequency = < 0x2faf080 >;    /* in zephyr/boards/st/stm32h7s78_dk/stm32h7s78_dk-common.dtsi:255 */
				spi-bus-width = < 0x8 >;               /* in zephyr/boards/st/stm32h7s78_dk/stm32h7s78_dk-common.dtsi:256 */
				data-rate = < 0x2 >;                   /* in zephyr/boards/st/stm32h7s78_dk/stm32h7s78_dk-common.dtsi:257 */
				four-byte-opcodes;                     /* in zephyr/boards/st/stm32h7s78_dk/stm32h7s78_dk-common.dtsi:258 */
				status = "okay";                       /* in zephyr/boards/st/stm32h7s78_dk/stm32h7s78_dk-common.dtsi:259 */
				#address-cells = < 0x1 >;              /* in zephyr/boards/st/stm32h7s78_dk/stm32h7s78_dk-common.dtsi:261 */
				#size-cells = < 0x1 >;                 /* in zephyr/boards/st/stm32h7s78_dk/stm32h7s78_dk-common.dtsi:262 */
				ranges = < 0x0 0x70000000 0x8000000 >; /* in zephyr/boards/st/stm32h7s78_dk/stm32h7s78_dk-common.dtsi:263 */

				/* node '/soc/spi@5200a000/xspi-nor-flash@0/ext-flash@0' defined in zephyr/boards/st/stm32h7s78_dk/stm32h7s78_dk-common.dtsi:265 */
				ext_flash: mx66uw1g45: ext-flash@0 {
					compatible = "soc-nv-flash";   /* in zephyr/boards/st/stm32h7s78_dk/stm32h7s78_dk-common.dtsi:266 */
					reg = < 0x0 0x8000000 >;       /* in zephyr/boards/st/stm32h7s78_dk/stm32h7s78_dk-common.dtsi:267 */
					write-block-size = < 0x1 >;    /* in zephyr/boards/st/stm32h7s78_dk/stm32h7s78_dk-common.dtsi:268 */
					erase-block-size = < 0x1000 >; /* in zephyr/boards/st/stm32h7s78_dk/stm32h7s78_dk-common.dtsi:269 */
					status = "okay";               /* in zephyr/boards/st/stm32h7s78_dk/stm32h7s78_dk.dts:21 */

					/* node '/soc/spi@5200a000/xspi-nor-flash@0/ext-flash@0/partitions' defined in zephyr/boards/st/stm32h7s78_dk/stm32h7s78_dk-common.dtsi:271 */
					partitions {
						compatible = "fixed-partitions"; /* in zephyr/boards/st/stm32h7s78_dk/stm32h7s78_dk.dts:24 */
						#address-cells = < 0x1 >;        /* in zephyr/boards/st/stm32h7s78_dk/stm32h7s78_dk.dts:25 */
						#size-cells = < 0x1 >;           /* in zephyr/boards/st/stm32h7s78_dk/stm32h7s78_dk.dts:26 */

						/* node '/soc/spi@5200a000/xspi-nor-flash@0/ext-flash@0/partitions/partition@0' defined in zephyr/boards/st/stm32h7s78_dk/stm32h7s78_dk.dts:28 */
						storage_partition: partition@0 {
							label = "storage";       /* in zephyr/boards/st/stm32h7s78_dk/stm32h7s78_dk.dts:29 */
							reg = < 0x0 0x8000000 >; /* in zephyr/boards/st/stm32h7s78_dk/stm32h7s78_dk.dts:30 */
						};
					};
				};
			};
		};

		/* node '/soc/watchdog@58004800' defined in zephyr/dts/arm/st/h7rs/stm32h7rs.dtsi:561 */
		iwdg: iwdg1: watchdog@58004800 {
			compatible = "st,stm32-watchdog"; /* in zephyr/dts/arm/st/h7rs/stm32h7rs.dtsi:562 */
			reg = < 0x58004800 0x400 >;       /* in zephyr/dts/arm/st/h7rs/stm32h7rs.dtsi:563 */
			interrupts = < 0x3 0x0 >;         /* in zephyr/dts/arm/st/h7rs/stm32h7rs.dtsi:564 */
			status = "okay";                  /* in zephyr/boards/st/stm32h7s78_dk/stm32h7s78_dk-common.dtsi:169 */
		};

		/* node '/soc/watchdog@40002c00' defined in zephyr/dts/arm/st/h7rs/stm32h7rs.dtsi:568 */
		wwdg: wwdg1: watchdog@40002c00 {
			compatible = "st,stm32-window-watchdog"; /* in zephyr/dts/arm/st/h7rs/stm32h7rs.dtsi:569 */
			reg = < 0x40002c00 0x1000 >;             /* in zephyr/dts/arm/st/h7rs/stm32h7rs.dtsi:570 */
			clocks = < &rcc 0x148 0x800 >;           /* in zephyr/dts/arm/st/h7rs/stm32h7rs.dtsi:571 */
			interrupts = < 0x4 0x7 >;                /* in zephyr/dts/arm/st/h7rs/stm32h7rs.dtsi:572 */
			status = "okay";                         /* in zephyr/boards/st/stm32h7s78_dk/stm32h7s78_dk-common.dtsi:173 */
		};

		/* node '/soc/timers@42000000' defined in zephyr/dts/arm/st/h7rs/stm32h7rs.dtsi:576 */
		timers1: timers@42000000 {
			compatible = "st,stm32-timers"; /* in zephyr/dts/arm/st/h7rs/stm32h7rs.dtsi:577 */
			reg = < 0x42000000 0x400 >;     /* in zephyr/dts/arm/st/h7rs/stm32h7rs.dtsi:578 */
			clocks = < &rcc 0x150 0x1 >,
			         < &rcc 0x1c 0xff >;    /* in zephyr/dts/arm/st/h7rs/stm32h7rs.dtsi:579 */
			resets = < &rctl 0x1300 >;      /* in zephyr/dts/arm/st/h7rs/stm32h7rs.dtsi:581 */
			interrupts = < 0x2f 0x0 >,
			             < 0x30 0x0 >,
			             < 0x31 0x0 >,
			             < 0x32 0x0 >;      /* in zephyr/dts/arm/st/h7rs/stm32h7rs.dtsi:582 */
			interrupt-names = "brk",
			                  "up",
			                  "trgcom",
			                  "cc";         /* in zephyr/dts/arm/st/h7rs/stm32h7rs.dtsi:583 */
			st,prescaler = < 0x0 >;         /* in zephyr/dts/arm/st/h7rs/stm32h7rs.dtsi:584 */
			status = "disabled";            /* in zephyr/dts/arm/st/h7rs/stm32h7rs.dtsi:585 */

			/* node '/soc/timers@42000000/pwm' defined in zephyr/dts/arm/st/h7rs/stm32h7rs.dtsi:587 */
			pwm {
				compatible = "st,stm32-pwm"; /* in zephyr/dts/arm/st/h7rs/stm32h7rs.dtsi:588 */
				status = "disabled";         /* in zephyr/dts/arm/st/h7rs/stm32h7rs.dtsi:589 */
				#pwm-cells = < 0x3 >;        /* in zephyr/dts/arm/st/h7rs/stm32h7rs.dtsi:590 */
			};
		};

		/* node '/soc/timers@40000000' defined in zephyr/dts/arm/st/h7rs/stm32h7rs.dtsi:594 */
		timers2: timers@40000000 {
			compatible = "st,stm32-timers"; /* in zephyr/dts/arm/st/h7rs/stm32h7rs.dtsi:595 */
			reg = < 0x40000000 0x400 >;     /* in zephyr/dts/arm/st/h7rs/stm32h7rs.dtsi:596 */
			clocks = < &rcc 0x148 0x1 >,
			         < &rcc 0x1b 0xff >;    /* in zephyr/dts/arm/st/h7rs/stm32h7rs.dtsi:597 */
			resets = < &rctl 0x1200 >;      /* in zephyr/dts/arm/st/h7rs/stm32h7rs.dtsi:599 */
			interrupts = < 0x33 0x0 >;      /* in zephyr/dts/arm/st/h7rs/stm32h7rs.dtsi:600 */
			interrupt-names = "global";     /* in zephyr/dts/arm/st/h7rs/stm32h7rs.dtsi:601 */
			st,prescaler = < 0x2710 >;      /* in zephyr/boards/st/stm32h7s78_dk/stm32h7s78_dk-common.dtsi:143 */
			status = "okay";                /* in zephyr/boards/st/stm32h7s78_dk/stm32h7s78_dk-common.dtsi:144 */

			/* node '/soc/timers@40000000/pwm' defined in zephyr/dts/arm/st/h7rs/stm32h7rs.dtsi:605 */
			pwm2: pwm {
				compatible = "st,stm32-pwm";   /* in zephyr/dts/arm/st/h7rs/stm32h7rs.dtsi:606 */
				#pwm-cells = < 0x3 >;          /* in zephyr/dts/arm/st/h7rs/stm32h7rs.dtsi:608 */
				status = "okay";               /* in zephyr/boards/st/stm32h7s78_dk/stm32h7s78_dk-common.dtsi:147 */
				pinctrl-0 = < &tim2_ch4_pa3 >; /* in zephyr/boards/st/stm32h7s78_dk/stm32h7s78_dk-common.dtsi:148 */
				pinctrl-names = "default";     /* in zephyr/boards/st/stm32h7s78_dk/stm32h7s78_dk-common.dtsi:149 */
			};

			/* node '/soc/timers@40000000/counter' defined in zephyr/dts/arm/st/h7rs/stm32h7rs.dtsi:611 */
			counter {
				compatible = "st,stm32-counter"; /* in zephyr/dts/arm/st/h7rs/stm32h7rs.dtsi:612 */
				status = "disabled";             /* in zephyr/dts/arm/st/h7rs/stm32h7rs.dtsi:613 */
			};
		};

		/* node '/soc/timers@40000400' defined in zephyr/dts/arm/st/h7rs/stm32h7rs.dtsi:617 */
		timers3: timers@40000400 {
			compatible = "st,stm32-timers"; /* in zephyr/dts/arm/st/h7rs/stm32h7rs.dtsi:618 */
			reg = < 0x40000400 0x400 >;     /* in zephyr/dts/arm/st/h7rs/stm32h7rs.dtsi:619 */
			clocks = < &rcc 0x148 0x2 >,
			         < &rcc 0x1b 0xff >;    /* in zephyr/dts/arm/st/h7rs/stm32h7rs.dtsi:620 */
			resets = < &rctl 0x1201 >;      /* in zephyr/dts/arm/st/h7rs/stm32h7rs.dtsi:622 */
			interrupts = < 0x34 0x0 >;      /* in zephyr/dts/arm/st/h7rs/stm32h7rs.dtsi:623 */
			interrupt-names = "global";     /* in zephyr/dts/arm/st/h7rs/stm32h7rs.dtsi:624 */
			st,prescaler = < 0x2710 >;      /* in zephyr/boards/st/stm32h7s78_dk/stm32h7s78_dk-common.dtsi:154 */
			status = "okay";                /* in zephyr/boards/st/stm32h7s78_dk/stm32h7s78_dk-common.dtsi:155 */

			/* node '/soc/timers@40000400/pwm' defined in zephyr/dts/arm/st/h7rs/stm32h7rs.dtsi:628 */
			pwm3: pwm {
				compatible = "st,stm32-pwm";   /* in zephyr/dts/arm/st/h7rs/stm32h7rs.dtsi:629 */
				#pwm-cells = < 0x3 >;          /* in zephyr/dts/arm/st/h7rs/stm32h7rs.dtsi:631 */
				status = "okay";               /* in zephyr/boards/st/stm32h7s78_dk/stm32h7s78_dk-common.dtsi:158 */
				pinctrl-0 = < &tim3_ch2_pb5 >; /* in zephyr/boards/st/stm32h7s78_dk/stm32h7s78_dk-common.dtsi:159 */
				pinctrl-names = "default";     /* in zephyr/boards/st/stm32h7s78_dk/stm32h7s78_dk-common.dtsi:160 */
			};

			/* node '/soc/timers@40000400/counter' defined in zephyr/dts/arm/st/h7rs/stm32h7rs.dtsi:634 */
			counter {
				compatible = "st,stm32-counter"; /* in zephyr/dts/arm/st/h7rs/stm32h7rs.dtsi:635 */
				status = "disabled";             /* in zephyr/dts/arm/st/h7rs/stm32h7rs.dtsi:636 */
			};
		};

		/* node '/soc/timers@40000800' defined in zephyr/dts/arm/st/h7rs/stm32h7rs.dtsi:640 */
		timers4: timers@40000800 {
			compatible = "st,stm32-timers"; /* in zephyr/dts/arm/st/h7rs/stm32h7rs.dtsi:641 */
			reg = < 0x40000800 0x400 >;     /* in zephyr/dts/arm/st/h7rs/stm32h7rs.dtsi:642 */
			clocks = < &rcc 0x148 0x4 >,
			         < &rcc 0x1b 0xff >;    /* in zephyr/dts/arm/st/h7rs/stm32h7rs.dtsi:643 */
			resets = < &rctl 0x1202 >;      /* in zephyr/dts/arm/st/h7rs/stm32h7rs.dtsi:645 */
			interrupts = < 0x35 0x0 >;      /* in zephyr/dts/arm/st/h7rs/stm32h7rs.dtsi:646 */
			interrupt-names = "global";     /* in zephyr/dts/arm/st/h7rs/stm32h7rs.dtsi:647 */
			st,prescaler = < 0x0 >;         /* in zephyr/dts/arm/st/h7rs/stm32h7rs.dtsi:648 */
			status = "disabled";            /* in zephyr/dts/arm/st/h7rs/stm32h7rs.dtsi:649 */

			/* node '/soc/timers@40000800/pwm' defined in zephyr/dts/arm/st/h7rs/stm32h7rs.dtsi:651 */
			pwm {
				compatible = "st,stm32-pwm"; /* in zephyr/dts/arm/st/h7rs/stm32h7rs.dtsi:652 */
				status = "disabled";         /* in zephyr/dts/arm/st/h7rs/stm32h7rs.dtsi:653 */
				#pwm-cells = < 0x3 >;        /* in zephyr/dts/arm/st/h7rs/stm32h7rs.dtsi:654 */
			};

			/* node '/soc/timers@40000800/counter' defined in zephyr/dts/arm/st/h7rs/stm32h7rs.dtsi:657 */
			counter {
				compatible = "st,stm32-counter"; /* in zephyr/dts/arm/st/h7rs/stm32h7rs.dtsi:658 */
				status = "disabled";             /* in zephyr/dts/arm/st/h7rs/stm32h7rs.dtsi:659 */
			};
		};

		/* node '/soc/timers@40000c00' defined in zephyr/dts/arm/st/h7rs/stm32h7rs.dtsi:663 */
		timers5: timers@40000c00 {
			compatible = "st,stm32-timers"; /* in zephyr/dts/arm/st/h7rs/stm32h7rs.dtsi:664 */
			reg = < 0x40000c00 0x400 >;     /* in zephyr/dts/arm/st/h7rs/stm32h7rs.dtsi:665 */
			clocks = < &rcc 0x148 0x8 >,
			         < &rcc 0x1b 0xff >;    /* in zephyr/dts/arm/st/h7rs/stm32h7rs.dtsi:666 */
			resets = < &rctl 0x1203 >;      /* in zephyr/dts/arm/st/h7rs/stm32h7rs.dtsi:668 */
			interrupts = < 0x36 0x0 >;      /* in zephyr/dts/arm/st/h7rs/stm32h7rs.dtsi:669 */
			interrupt-names = "global";     /* in zephyr/dts/arm/st/h7rs/stm32h7rs.dtsi:670 */
			st,prescaler = < 0x0 >;         /* in zephyr/dts/arm/st/h7rs/stm32h7rs.dtsi:671 */
			status = "disabled";            /* in zephyr/dts/arm/st/h7rs/stm32h7rs.dtsi:672 */

			/* node '/soc/timers@40000c00/pwm' defined in zephyr/dts/arm/st/h7rs/stm32h7rs.dtsi:674 */
			pwm {
				compatible = "st,stm32-pwm"; /* in zephyr/dts/arm/st/h7rs/stm32h7rs.dtsi:675 */
				status = "disabled";         /* in zephyr/dts/arm/st/h7rs/stm32h7rs.dtsi:676 */
				#pwm-cells = < 0x3 >;        /* in zephyr/dts/arm/st/h7rs/stm32h7rs.dtsi:677 */
			};

			/* node '/soc/timers@40000c00/counter' defined in zephyr/dts/arm/st/h7rs/stm32h7rs.dtsi:680 */
			counter {
				compatible = "st,stm32-counter"; /* in zephyr/dts/arm/st/h7rs/stm32h7rs.dtsi:681 */
				status = "disabled";             /* in zephyr/dts/arm/st/h7rs/stm32h7rs.dtsi:682 */
			};
		};

		/* node '/soc/timers@40001000' defined in zephyr/dts/arm/st/h7rs/stm32h7rs.dtsi:686 */
		timers6: timers@40001000 {
			compatible = "st,stm32-timers"; /* in zephyr/dts/arm/st/h7rs/stm32h7rs.dtsi:687 */
			reg = < 0x40001000 0x400 >;     /* in zephyr/dts/arm/st/h7rs/stm32h7rs.dtsi:688 */
			clocks = < &rcc 0x148 0x10 >,
			         < &rcc 0x1b 0xff >;    /* in zephyr/dts/arm/st/h7rs/stm32h7rs.dtsi:689 */
			resets = < &rctl 0x1204 >;      /* in zephyr/dts/arm/st/h7rs/stm32h7rs.dtsi:691 */
			interrupts = < 0x37 0x0 >;      /* in zephyr/dts/arm/st/h7rs/stm32h7rs.dtsi:692 */
			interrupt-names = "global";     /* in zephyr/dts/arm/st/h7rs/stm32h7rs.dtsi:693 */
			st,prescaler = < 0x0 >;         /* in zephyr/dts/arm/st/h7rs/stm32h7rs.dtsi:694 */
			status = "disabled";            /* in zephyr/dts/arm/st/h7rs/stm32h7rs.dtsi:695 */

			/* node '/soc/timers@40001000/counter' defined in zephyr/dts/arm/st/h7rs/stm32h7rs.dtsi:697 */
			counter {
				compatible = "st,stm32-counter"; /* in zephyr/dts/arm/st/h7rs/stm32h7rs.dtsi:698 */
				status = "disabled";             /* in zephyr/dts/arm/st/h7rs/stm32h7rs.dtsi:699 */
			};
		};

		/* node '/soc/timers@40001400' defined in zephyr/dts/arm/st/h7rs/stm32h7rs.dtsi:703 */
		timers7: timers@40001400 {
			compatible = "st,stm32-timers"; /* in zephyr/dts/arm/st/h7rs/stm32h7rs.dtsi:704 */
			reg = < 0x40001400 0x400 >;     /* in zephyr/dts/arm/st/h7rs/stm32h7rs.dtsi:705 */
			clocks = < &rcc 0x148 0x20 >,
			         < &rcc 0x1b 0xff >;    /* in zephyr/dts/arm/st/h7rs/stm32h7rs.dtsi:706 */
			resets = < &rctl 0x1205 >;      /* in zephyr/dts/arm/st/h7rs/stm32h7rs.dtsi:708 */
			interrupts = < 0x38 0x0 >;      /* in zephyr/dts/arm/st/h7rs/stm32h7rs.dtsi:709 */
			interrupt-names = "global";     /* in zephyr/dts/arm/st/h7rs/stm32h7rs.dtsi:710 */
			st,prescaler = < 0x0 >;         /* in zephyr/dts/arm/st/h7rs/stm32h7rs.dtsi:711 */
			status = "disabled";            /* in zephyr/dts/arm/st/h7rs/stm32h7rs.dtsi:712 */

			/* node '/soc/timers@40001400/counter' defined in zephyr/dts/arm/st/h7rs/stm32h7rs.dtsi:714 */
			counter {
				compatible = "st,stm32-counter"; /* in zephyr/dts/arm/st/h7rs/stm32h7rs.dtsi:715 */
				status = "disabled";             /* in zephyr/dts/arm/st/h7rs/stm32h7rs.dtsi:716 */
			};
		};

		/* node '/soc/timers@42004c00' defined in zephyr/dts/arm/st/h7rs/stm32h7rs.dtsi:720 */
		timers9: timers@42004c00 {
			compatible = "st,stm32-timers";  /* in zephyr/dts/arm/st/h7rs/stm32h7rs.dtsi:721 */
			reg = < 0x42004c00 0x400 >;      /* in zephyr/dts/arm/st/h7rs/stm32h7rs.dtsi:722 */
			clocks = < &rcc 0x150 0x80000 >,
			         < &rcc 0x1c 0xff >;     /* in zephyr/dts/arm/st/h7rs/stm32h7rs.dtsi:723 */
			resets = < &rctl 0x1313 >;       /* in zephyr/dts/arm/st/h7rs/stm32h7rs.dtsi:725 */
			interrupts = < 0x39 0x0 >;       /* in zephyr/dts/arm/st/h7rs/stm32h7rs.dtsi:726 */
			interrupt-names = "global";      /* in zephyr/dts/arm/st/h7rs/stm32h7rs.dtsi:727 */
			st,prescaler = < 0x0 >;          /* in zephyr/dts/arm/st/h7rs/stm32h7rs.dtsi:728 */
			status = "disabled";             /* in zephyr/dts/arm/st/h7rs/stm32h7rs.dtsi:729 */

			/* node '/soc/timers@42004c00/counter' defined in zephyr/dts/arm/st/h7rs/stm32h7rs.dtsi:731 */
			counter {
				compatible = "st,stm32-counter"; /* in zephyr/dts/arm/st/h7rs/stm32h7rs.dtsi:732 */
				status = "disabled";             /* in zephyr/dts/arm/st/h7rs/stm32h7rs.dtsi:733 */
			};
		};

		/* node '/soc/timers@42004000' defined in zephyr/dts/arm/st/h7rs/stm32h7rs.dtsi:737 */
		timers15: timers@42004000 {
			compatible = "st,stm32-timers";  /* in zephyr/dts/arm/st/h7rs/stm32h7rs.dtsi:738 */
			reg = < 0x42004000 0x400 >;      /* in zephyr/dts/arm/st/h7rs/stm32h7rs.dtsi:739 */
			clocks = < &rcc 0x150 0x10000 >,
			         < &rcc 0x1c 0xff >;     /* in zephyr/dts/arm/st/h7rs/stm32h7rs.dtsi:740 */
			resets = < &rctl 0x1310 >;       /* in zephyr/dts/arm/st/h7rs/stm32h7rs.dtsi:742 */
			interrupts = < 0x74 0x0 >;       /* in zephyr/dts/arm/st/h7rs/stm32h7rs.dtsi:743 */
			interrupt-names = "global";      /* in zephyr/dts/arm/st/h7rs/stm32h7rs.dtsi:744 */
			st,prescaler = < 0x0 >;          /* in zephyr/dts/arm/st/h7rs/stm32h7rs.dtsi:745 */
			status = "disabled";             /* in zephyr/dts/arm/st/h7rs/stm32h7rs.dtsi:746 */

			/* node '/soc/timers@42004000/pwm' defined in zephyr/dts/arm/st/h7rs/stm32h7rs.dtsi:748 */
			pwm {
				compatible = "st,stm32-pwm"; /* in zephyr/dts/arm/st/h7rs/stm32h7rs.dtsi:749 */
				status = "disabled";         /* in zephyr/dts/arm/st/h7rs/stm32h7rs.dtsi:750 */
				#pwm-cells = < 0x3 >;        /* in zephyr/dts/arm/st/h7rs/stm32h7rs.dtsi:751 */
			};

			/* node '/soc/timers@42004000/counter' defined in zephyr/dts/arm/st/h7rs/stm32h7rs.dtsi:754 */
			counter {
				compatible = "st,stm32-counter"; /* in zephyr/dts/arm/st/h7rs/stm32h7rs.dtsi:755 */
				status = "disabled";             /* in zephyr/dts/arm/st/h7rs/stm32h7rs.dtsi:756 */
			};
		};

		/* node '/soc/timers@42004400' defined in zephyr/dts/arm/st/h7rs/stm32h7rs.dtsi:760 */
		timers16: timers@42004400 {
			compatible = "st,stm32-timers";  /* in zephyr/dts/arm/st/h7rs/stm32h7rs.dtsi:761 */
			reg = < 0x42004400 0x400 >;      /* in zephyr/dts/arm/st/h7rs/stm32h7rs.dtsi:762 */
			clocks = < &rcc 0x150 0x20000 >,
			         < &rcc 0x1c 0xff >;     /* in zephyr/dts/arm/st/h7rs/stm32h7rs.dtsi:763 */
			resets = < &rctl 0x1311 >;       /* in zephyr/dts/arm/st/h7rs/stm32h7rs.dtsi:765 */
			interrupts = < 0x75 0x0 >;       /* in zephyr/dts/arm/st/h7rs/stm32h7rs.dtsi:766 */
			interrupt-names = "global";      /* in zephyr/dts/arm/st/h7rs/stm32h7rs.dtsi:767 */
			st,prescaler = < 0x0 >;          /* in zephyr/dts/arm/st/h7rs/stm32h7rs.dtsi:768 */
			status = "disabled";             /* in zephyr/dts/arm/st/h7rs/stm32h7rs.dtsi:769 */

			/* node '/soc/timers@42004400/pwm' defined in zephyr/dts/arm/st/h7rs/stm32h7rs.dtsi:771 */
			pwm {
				compatible = "st,stm32-pwm"; /* in zephyr/dts/arm/st/h7rs/stm32h7rs.dtsi:772 */
				status = "disabled";         /* in zephyr/dts/arm/st/h7rs/stm32h7rs.dtsi:773 */
				#pwm-cells = < 0x3 >;        /* in zephyr/dts/arm/st/h7rs/stm32h7rs.dtsi:774 */
			};

			/* node '/soc/timers@42004400/counter' defined in zephyr/dts/arm/st/h7rs/stm32h7rs.dtsi:777 */
			counter {
				compatible = "st,stm32-counter"; /* in zephyr/dts/arm/st/h7rs/stm32h7rs.dtsi:778 */
				status = "disabled";             /* in zephyr/dts/arm/st/h7rs/stm32h7rs.dtsi:779 */
			};
		};

		/* node '/soc/timers@42004800' defined in zephyr/dts/arm/st/h7rs/stm32h7rs.dtsi:783 */
		timers17: timers@42004800 {
			compatible = "st,stm32-timers";  /* in zephyr/dts/arm/st/h7rs/stm32h7rs.dtsi:784 */
			reg = < 0x42004800 0x400 >;      /* in zephyr/dts/arm/st/h7rs/stm32h7rs.dtsi:785 */
			clocks = < &rcc 0x150 0x40000 >,
			         < &rcc 0x1c 0xff >;     /* in zephyr/dts/arm/st/h7rs/stm32h7rs.dtsi:786 */
			resets = < &rctl 0x1312 >;       /* in zephyr/dts/arm/st/h7rs/stm32h7rs.dtsi:788 */
			interrupts = < 0x76 0x0 >;       /* in zephyr/dts/arm/st/h7rs/stm32h7rs.dtsi:789 */
			interrupt-names = "global";      /* in zephyr/dts/arm/st/h7rs/stm32h7rs.dtsi:790 */
			st,prescaler = < 0x0 >;          /* in zephyr/dts/arm/st/h7rs/stm32h7rs.dtsi:791 */
			status = "disabled";             /* in zephyr/dts/arm/st/h7rs/stm32h7rs.dtsi:792 */

			/* node '/soc/timers@42004800/pwm' defined in zephyr/dts/arm/st/h7rs/stm32h7rs.dtsi:794 */
			pwm {
				compatible = "st,stm32-pwm"; /* in zephyr/dts/arm/st/h7rs/stm32h7rs.dtsi:795 */
				status = "disabled";         /* in zephyr/dts/arm/st/h7rs/stm32h7rs.dtsi:796 */
				#pwm-cells = < 0x3 >;        /* in zephyr/dts/arm/st/h7rs/stm32h7rs.dtsi:797 */
			};

			/* node '/soc/timers@42004800/counter' defined in zephyr/dts/arm/st/h7rs/stm32h7rs.dtsi:800 */
			counter {
				compatible = "st,stm32-counter"; /* in zephyr/dts/arm/st/h7rs/stm32h7rs.dtsi:801 */
				status = "disabled";             /* in zephyr/dts/arm/st/h7rs/stm32h7rs.dtsi:802 */
			};
		};

		/* node '/soc/timers@40002400' defined in zephyr/dts/arm/st/h7rs/stm32h7rs.dtsi:806 */
		lptim1: timers@40002400 {
			compatible = "st,stm32-lptim"; /* in zephyr/dts/arm/st/h7rs/stm32h7rs.dtsi:807 */
			clocks = < &rcc 0x148 0x200 >; /* in zephyr/dts/arm/st/h7rs/stm32h7rs.dtsi:808 */
			#address-cells = < 0x1 >;      /* in zephyr/dts/arm/st/h7rs/stm32h7rs.dtsi:809 */
			#size-cells = < 0x0 >;         /* in zephyr/dts/arm/st/h7rs/stm32h7rs.dtsi:810 */
			reg = < 0x40002400 0x400 >;    /* in zephyr/dts/arm/st/h7rs/stm32h7rs.dtsi:811 */
			interrupts = < 0x77 0x1 >;     /* in zephyr/dts/arm/st/h7rs/stm32h7rs.dtsi:812 */
			interrupt-names = "wakeup";    /* in zephyr/dts/arm/st/h7rs/stm32h7rs.dtsi:813 */
			status = "disabled";           /* in zephyr/dts/arm/st/h7rs/stm32h7rs.dtsi:814 */
		};

		/* node '/soc/adc@40022000' defined in zephyr/dts/arm/st/h7rs/stm32h7rs.dtsi:817 */
		adc1: adc@40022000 {
			compatible = "st,stm32-adc";                                /* in zephyr/dts/arm/st/h7rs/stm32h7rs.dtsi:818 */
			reg = < 0x40022000 0x400 >;                                 /* in zephyr/dts/arm/st/h7rs/stm32h7rs.dtsi:819 */
			clocks = < &rcc 0x138 0x20 >;                               /* in zephyr/dts/arm/st/h7rs/stm32h7rs.dtsi:820 */
			clock-names = "adcx";                                       /* in zephyr/dts/arm/st/h7rs/stm32h7rs.dtsi:821 */
			interrupts = < 0x26 0x0 >;                                  /* in zephyr/dts/arm/st/h7rs/stm32h7rs.dtsi:822 */
			#io-channel-cells = < 0x1 >;                                /* in zephyr/dts/arm/st/h7rs/stm32h7rs.dtsi:823 */
			resolutions = < 0x60e20c 0x51e20c 0x42e20c 0x33e20c >;      /* in zephyr/dts/arm/st/h7rs/stm32h7rs.dtsi:824 */
			sampling-times = < 0x3 0x7 0xd 0x19 0x30 0x5d 0xf8 0x281 >; /* in zephyr/dts/arm/st/h7rs/stm32h7rs.dtsi:828 */
			st,adc-sequencer = "programmable";                          /* in zephyr/dts/arm/st/h7rs/stm32h7rs.dtsi:829 */
			st,adc-oversampler = "minimal";                             /* in zephyr/dts/arm/st/h7rs/stm32h7rs.dtsi:830 */
			st,adc-internal-regulator = "startup-sw-delay";             /* in zephyr/dts/arm/st/h7rs/stm32h7rs.dtsi:831 */
			st,adc-has-deep-powerdown;                                  /* in zephyr/dts/arm/st/h7rs/stm32h7rs.dtsi:832 */
			st,adc-has-differential-support;                            /* in zephyr/dts/arm/st/h7rs/stm32h7rs.dtsi:833 */
			pinctrl-0 = < &adc1_inp6_pf12 >;                            /* in zephyr/boards/st/stm32h7s78_dk/stm32h7s78_dk-common.dtsi:177 */
			pinctrl-names = "default";                                  /* in zephyr/boards/st/stm32h7s78_dk/stm32h7s78_dk-common.dtsi:178 */
			st,adc-clock-source = "SYNC";                               /* in zephyr/boards/st/stm32h7s78_dk/stm32h7s78_dk-common.dtsi:179 */
			st,adc-prescaler = < 0x4 >;                                 /* in zephyr/boards/st/stm32h7s78_dk/stm32h7s78_dk-common.dtsi:180 */
			status = "okay";                                            /* in zephyr/boards/st/stm32h7s78_dk/stm32h7s78_dk-common.dtsi:181 */
			phandle = < 0x55 >;                                         /* in zephyr/dts/arm/st/h7rs/stm32h7rs.dtsi:964 */
		};

		/* node '/soc/adc@40022100' defined in zephyr/dts/arm/st/h7rs/stm32h7rs.dtsi:837 */
		adc2: adc@40022100 {
			compatible = "st,stm32-adc";                                /* in zephyr/dts/arm/st/h7rs/stm32h7rs.dtsi:838 */
			reg = < 0x40022100 0x400 >;                                 /* in zephyr/dts/arm/st/h7rs/stm32h7rs.dtsi:839 */
			clocks = < &rcc 0x138 0x20 >;                               /* in zephyr/dts/arm/st/h7rs/stm32h7rs.dtsi:840 */
			clock-names = "adcx";                                       /* in zephyr/dts/arm/st/h7rs/stm32h7rs.dtsi:841 */
			interrupts = < 0x26 0x0 >;                                  /* in zephyr/dts/arm/st/h7rs/stm32h7rs.dtsi:842 */
			#io-channel-cells = < 0x1 >;                                /* in zephyr/dts/arm/st/h7rs/stm32h7rs.dtsi:843 */
			resolutions = < 0x60e20c 0x51e20c 0x42e20c 0x33e20c >;      /* in zephyr/dts/arm/st/h7rs/stm32h7rs.dtsi:844 */
			sampling-times = < 0x3 0x7 0xd 0x19 0x30 0x5d 0xf8 0x281 >; /* in zephyr/dts/arm/st/h7rs/stm32h7rs.dtsi:848 */
			st,adc-sequencer = "programmable";                          /* in zephyr/dts/arm/st/h7rs/stm32h7rs.dtsi:849 */
			st,adc-oversampler = "minimal";                             /* in zephyr/dts/arm/st/h7rs/stm32h7rs.dtsi:850 */
			st,adc-internal-regulator = "startup-sw-delay";             /* in zephyr/dts/arm/st/h7rs/stm32h7rs.dtsi:851 */
			st,adc-has-deep-powerdown;                                  /* in zephyr/dts/arm/st/h7rs/stm32h7rs.dtsi:852 */
			st,adc-has-differential-support;                            /* in zephyr/dts/arm/st/h7rs/stm32h7rs.dtsi:853 */
			pinctrl-0 = < &adc2_inp2_pf13 >;                            /* in zephyr/boards/st/stm32h7s78_dk/stm32h7s78_dk-common.dtsi:185 */
			pinctrl-names = "default";                                  /* in zephyr/boards/st/stm32h7s78_dk/stm32h7s78_dk-common.dtsi:186 */
			st,adc-clock-source = "SYNC";                               /* in zephyr/boards/st/stm32h7s78_dk/stm32h7s78_dk-common.dtsi:187 */
			st,adc-prescaler = < 0x4 >;                                 /* in zephyr/boards/st/stm32h7s78_dk/stm32h7s78_dk-common.dtsi:188 */
			status = "okay";                                            /* in zephyr/boards/st/stm32h7s78_dk/stm32h7s78_dk-common.dtsi:189 */
			phandle = < 0x56 >;                                         /* in zephyr/dts/arm/st/h7rs/stm32h7rs.dtsi:972 */
		};

		/* node '/soc/rng@48020000' defined in zephyr/dts/arm/st/h7rs/stm32h7rs.dtsi:857 */
		rng: rng@48020000 {
			compatible = "st,stm32-rng"; /* in zephyr/dts/arm/st/h7rs/stm32h7rs.dtsi:858 */
			reg = < 0x48020000 0x400 >;  /* in zephyr/dts/arm/st/h7rs/stm32h7rs.dtsi:859 */
			clocks = < &rcc 0x158 0x1 >; /* in zephyr/dts/arm/st/h7rs/stm32h7rs.dtsi:860 */
			interrupts = < 0x25 0x0 >;   /* in zephyr/dts/arm/st/h7rs/stm32h7rs.dtsi:861 */
			status = "okay";             /* in zephyr/boards/st/stm32h7s78_dk/stm32h7s78_dk-common.dtsi:165 */
		};

		/* node '/soc/ethernet@40028000' defined in zephyr/dts/arm/st/h7rs/stm32h7rs.dtsi:865 */
		ethernet@40028000 {
			reg = < 0x40028000 0x8000 >;                 /* in zephyr/dts/arm/st/h7rs/stm32h7rs.dtsi:866 */
			compatible = "st,stm32-ethernet-controller"; /* in zephyr/dts/arm/st/h7rs/stm32h7rs.dtsi:867 */
			clock-names = "stm-eth";                     /* in zephyr/dts/arm/st/h7rs/stm32h7rs.dtsi:868 */
			clocks = < &rcc 0x138 0x8000 >;              /* in zephyr/dts/arm/st/h7rs/stm32h7rs.dtsi:869 */

			/* node '/soc/ethernet@40028000/ethernet' defined in zephyr/dts/arm/st/h7rs/stm32h7rs.dtsi:871 */
			mac: ethernet {
				compatible = "st,stm32h7-ethernet",
				             "st,stm32-ethernet";   /* in zephyr/dts/arm/st/h7rs/stm32h7rs.dtsi:872 */
				interrupts = < 0x5c 0x0 >;          /* in zephyr/dts/arm/st/h7rs/stm32h7rs.dtsi:873 */
				clock-names = "mac-clk-tx",
				              "mac-clk-rx";         /* in zephyr/dts/arm/st/h7rs/stm32h7rs.dtsi:874 */
				clocks = < &rcc 0x138 0x10000 >,
				         < &rcc 0x138 0x20000 >;    /* in zephyr/dts/arm/st/h7rs/stm32h7rs.dtsi:875 */
				status = "disabled";                /* in zephyr/dts/arm/st/h7rs/stm32h7rs.dtsi:877 */
			};

			/* node '/soc/ethernet@40028000/mdio' defined in zephyr/dts/arm/st/h7rs/stm32h7rs.dtsi:880 */
			mdio: mdio {
				compatible = "st,stm32-mdio"; /* in zephyr/dts/arm/st/h7rs/stm32h7rs.dtsi:881 */
				#address-cells = < 0x1 >;     /* in zephyr/dts/arm/st/h7rs/stm32h7rs.dtsi:882 */
				#size-cells = < 0x0 >;        /* in zephyr/dts/arm/st/h7rs/stm32h7rs.dtsi:883 */
				status = "disabled";          /* in zephyr/dts/arm/st/h7rs/stm32h7rs.dtsi:884 */
			};
		};

		/* node '/soc/usb@40080000' defined in zephyr/dts/arm/st/h7rs/stm32h7rs.dtsi:888 */
		usbotg_fs: usb2: zephyr_udc0: usb@40080000 {
			compatible = "st,stm32-otgfs";                           /* in zephyr/dts/arm/st/h7rs/stm32h7rs.dtsi:889 */
			reg = < 0x40080000 0x40000 >;                            /* in zephyr/dts/arm/st/h7rs/stm32h7rs.dtsi:890 */
			interrupts = < 0x70 0x0 >;                               /* in zephyr/dts/arm/st/h7rs/stm32h7rs.dtsi:891 */
			interrupt-names = "otgfs";                               /* in zephyr/dts/arm/st/h7rs/stm32h7rs.dtsi:892 */
			num-bidir-endpoints = < 0x6 >;                           /* in zephyr/dts/arm/st/h7rs/stm32h7rs.dtsi:893 */
			ram-size = < 0x500 >;                                    /* in zephyr/dts/arm/st/h7rs/stm32h7rs.dtsi:894 */
			maximum-speed = "full-speed";                            /* in zephyr/dts/arm/st/h7rs/stm32h7rs.dtsi:895 */
			phys = < &otgfs_phy >;                                   /* in zephyr/dts/arm/st/h7rs/stm32h7rs.dtsi:896 */
			clocks = < &rcc 0x138 0x8000000 >,
			         < &rcc 0x5 0x2e004c >;                          /* in zephyr/dts/arm/st/h7rs/stm32h7rs.dtsi:897 */
			pinctrl-0 = < &usb_otg_fs_dm_pm12 &usb_otg_fs_dp_pm11 >; /* in zephyr/boards/st/stm32h7s78_dk/stm32h7s78_dk-common.dtsi:293 */
			pinctrl-names = "default";                               /* in zephyr/boards/st/stm32h7s78_dk/stm32h7s78_dk-common.dtsi:294 */
			status = "okay";                                         /* in zephyr/boards/st/stm32h7s78_dk/stm32h7s78_dk-common.dtsi:295 */
		};

		/* node '/soc/dma@40021000' defined in zephyr/dts/arm/st/h7rs/stm32h7rs.dtsi:902 */
		gpdma1: dma@40021000 {
			compatible = "st,stm32u5-dma";                                                                  /* in zephyr/dts/arm/st/h7rs/stm32h7rs.dtsi:903 */
			#dma-cells = < 0x3 >;                                                                           /* in zephyr/dts/arm/st/h7rs/stm32h7rs.dtsi:904 */
			reg = < 0x40021000 0x1000 >;                                                                    /* in zephyr/dts/arm/st/h7rs/stm32h7rs.dtsi:905 */
			clocks = < &rcc 0x138 0x10 >;                                                                   /* in zephyr/dts/arm/st/h7rs/stm32h7rs.dtsi:906 */
			interrupts = < 0x27 0x0 0x28 0x0 0x29 0x0 0x2a 0x0 0x2b 0x0 0x2c 0x0 0x2d 0x0 0x2e 0x0 0x85 0x0
			               0x86 0x0 0x87 0x0 0x88 0x0 0x89 0x0 0x8a 0x0 0x8b 0x0 0x8c 0x0 >;                /* in zephyr/dts/arm/st/h7rs/stm32h7rs.dtsi:907 */
			dma-channels = < 0x10 >;                                                                        /* in zephyr/dts/arm/st/h7rs/stm32h7rs.dtsi:909 */
			dma-requests = < 0x6d >;                                                                        /* in zephyr/dts/arm/st/h7rs/stm32h7rs.dtsi:910 */
			dma-offset = < 0x0 >;                                                                           /* in zephyr/dts/arm/st/h7rs/stm32h7rs.dtsi:911 */
			status = "disabled";                                                                            /* in zephyr/dts/arm/st/h7rs/stm32h7rs.dtsi:912 */
			phandle = < 0x36 >;                                                                             /* in zephyr/dts/arm/st/h7rs/stm32h7rs.dtsi:922 */
		};

		/* node '/soc/sai1@42005804' defined in zephyr/dts/arm/st/h7rs/stm32h7rs.dtsi:915 */
		sai1_a: sai1@42005804 {
			compatible = "st,stm32-sai";         /* in zephyr/dts/arm/st/h7rs/stm32h7rs.dtsi:916 */
			#address-cells = < 0x1 >;            /* in zephyr/dts/arm/st/h7rs/stm32h7rs.dtsi:917 */
			#size-cells = < 0x0 >;               /* in zephyr/dts/arm/st/h7rs/stm32h7rs.dtsi:918 */
			reg = < 0x42005804 0x20 >;           /* in zephyr/dts/arm/st/h7rs/stm32h7rs.dtsi:919 */
			clocks = < &rcc 0x150 0x400000 >,
			         < &rcc 0x11 0x2500054 >;    /* in zephyr/dts/arm/st/h7rs/stm32h7rs.dtsi:920 */
			dmas = < &gpdma1 0x1 0x3f 0x22800 >; /* in zephyr/dts/arm/st/h7rs/stm32h7rs.dtsi:922 */
			status = "disabled";                 /* in zephyr/dts/arm/st/h7rs/stm32h7rs.dtsi:924 */
		};

		/* node '/soc/sai1@42005824' defined in zephyr/dts/arm/st/h7rs/stm32h7rs.dtsi:927 */
		sai1_b: sai1@42005824 {
			compatible = "st,stm32-sai";         /* in zephyr/dts/arm/st/h7rs/stm32h7rs.dtsi:928 */
			#address-cells = < 0x1 >;            /* in zephyr/dts/arm/st/h7rs/stm32h7rs.dtsi:929 */
			#size-cells = < 0x0 >;               /* in zephyr/dts/arm/st/h7rs/stm32h7rs.dtsi:930 */
			reg = < 0x42005824 0x20 >;           /* in zephyr/dts/arm/st/h7rs/stm32h7rs.dtsi:931 */
			clocks = < &rcc 0x150 0x400000 >,
			         < &rcc 0x11 0x2500054 >;    /* in zephyr/dts/arm/st/h7rs/stm32h7rs.dtsi:932 */
			dmas = < &gpdma1 0x0 0x40 0x22800 >; /* in zephyr/dts/arm/st/h7rs/stm32h7rs.dtsi:934 */
			status = "disabled";                 /* in zephyr/dts/arm/st/h7rs/stm32h7rs.dtsi:936 */
		};

		/* node '/soc/ltdc@50001000' defined in zephyr/dts/arm/st/h7rs/stm32h7rs.dtsi:939 */
		ltdc: ltdc@50001000 {
			compatible = "st,stm32-ltdc";                                                                               /* in zephyr/dts/arm/st/h7rs/stm32h7rs.dtsi:940 */
			reg = < 0x50001000 0x400 >;                                                                                 /* in zephyr/dts/arm/st/h7rs/stm32h7rs.dtsi:941 */
			interrupts = < 0x60 0x0 >,
			             < 0x61 0x0 >;                                                                                  /* in zephyr/dts/arm/st/h7rs/stm32h7rs.dtsi:942 */
			interrupt-names = "ltdc",
			                  "ltdc_er";                                                                                /* in zephyr/dts/arm/st/h7rs/stm32h7rs.dtsi:943 */
			clocks = < &rcc 0x144 0x2 >,
			         < &rcc 0x13 0xff >;                                                                                /* in zephyr/dts/arm/st/h7rs/stm32h7rs.dtsi:944 */
			resets = < &rctl 0x1181 >;                                                                                  /* in zephyr/dts/arm/st/h7rs/stm32h7rs.dtsi:946 */
			pinctrl-0 = < &ltdc_r0_pf9 &ltdc_r1_pf10 &ltdc_r2_pf0 &ltdc_r3_pb4 &ltdc_r4_pb3 &ltdc_r5_pa15 &ltdc_r6_pg1
			              &ltdc_r7_pg0 &ltdc_g0_pf7 &ltdc_g1_pf15 &ltdc_g2_pa1 &ltdc_g3_pa0 &ltdc_g4_pb13 &ltdc_g5_pb12
			              &ltdc_g6_pb11 &ltdc_g7_pb15 &ltdc_b0_pf11 &ltdc_b1_pg14 &ltdc_b2_pa12 &ltdc_b3_pa11
			              &ltdc_b4_pa10 &ltdc_b5_pa9 &ltdc_b6_pa8 &ltdc_b7_pa6 &ltdc_de_pb14 &ltdc_clk_pg13
			              &ltdc_hsync_pg2 &ltdc_vsync_pe11 >;                                                           /* in zephyr/boards/st/stm32h7s78_dk/stm32h7s78_dk-common.dtsi:301 */
			pinctrl-names = "default";                                                                                  /* in zephyr/boards/st/stm32h7s78_dk/stm32h7s78_dk-common.dtsi:308 */
			disp-on-gpios = < &gpioe 0xf 0x0 >;                                                                         /* in zephyr/boards/st/stm32h7s78_dk/stm32h7s78_dk-common.dtsi:309 */
			bl-ctrl-gpios = < &gpiog 0xf 0x0 >;                                                                         /* in zephyr/boards/st/stm32h7s78_dk/stm32h7s78_dk-common.dtsi:310 */
			status = "okay";                                                                                            /* in zephyr/boards/st/stm32h7s78_dk/stm32h7s78_dk-common.dtsi:312 */
			width = < 0x320 >;                                                                                          /* in zephyr/boards/st/stm32h7s78_dk/stm32h7s78_dk-common.dtsi:314 */
			height = < 0x1e0 >;                                                                                         /* in zephyr/boards/st/stm32h7s78_dk/stm32h7s78_dk-common.dtsi:315 */
			pixel-format = < 0x10 >;                                                                                    /* in zephyr/boards/st/stm32h7s78_dk/stm32h7s78_dk-common.dtsi:316 */
			def-back-color-red = < 0xff >;                                                                              /* in zephyr/boards/st/stm32h7s78_dk/stm32h7s78_dk-common.dtsi:332 */
			def-back-color-green = < 0xff >;                                                                            /* in zephyr/boards/st/stm32h7s78_dk/stm32h7s78_dk-common.dtsi:333 */
			def-back-color-blue = < 0xff >;                                                                             /* in zephyr/boards/st/stm32h7s78_dk/stm32h7s78_dk-common.dtsi:334 */

			/* node '/soc/ltdc@50001000/display-timings' defined in zephyr/boards/st/stm32h7s78_dk/stm32h7s78_dk-common.dtsi:318 */
			display-timings {
				compatible = "zephyr,panel-timing"; /* in zephyr/boards/st/stm32h7s78_dk/stm32h7s78_dk-common.dtsi:319 */
				de-active = < 0x0 >;                /* in zephyr/boards/st/stm32h7s78_dk/stm32h7s78_dk-common.dtsi:320 */
				pixelclk-active = < 0x0 >;          /* in zephyr/boards/st/stm32h7s78_dk/stm32h7s78_dk-common.dtsi:321 */
				hsync-active = < 0x0 >;             /* in zephyr/boards/st/stm32h7s78_dk/stm32h7s78_dk-common.dtsi:322 */
				vsync-active = < 0x0 >;             /* in zephyr/boards/st/stm32h7s78_dk/stm32h7s78_dk-common.dtsi:323 */
				hsync-len = < 0x4 >;                /* in zephyr/boards/st/stm32h7s78_dk/stm32h7s78_dk-common.dtsi:324 */
				vsync-len = < 0x4 >;                /* in zephyr/boards/st/stm32h7s78_dk/stm32h7s78_dk-common.dtsi:325 */
				hback-porch = < 0x8 >;              /* in zephyr/boards/st/stm32h7s78_dk/stm32h7s78_dk-common.dtsi:326 */
				vback-porch = < 0x8 >;              /* in zephyr/boards/st/stm32h7s78_dk/stm32h7s78_dk-common.dtsi:327 */
				hfront-porch = < 0x8 >;             /* in zephyr/boards/st/stm32h7s78_dk/stm32h7s78_dk-common.dtsi:328 */
				vfront-porch = < 0x8 >;             /* in zephyr/boards/st/stm32h7s78_dk/stm32h7s78_dk-common.dtsi:329 */
			};
		};
	};

	/* node '/cpus' defined in zephyr/dts/arm/st/h7rs/stm32h7rs.dtsi:34 */
	cpus {
		#address-cells = < 0x1 >; /* in zephyr/dts/arm/st/h7rs/stm32h7rs.dtsi:35 */
		#size-cells = < 0x0 >;    /* in zephyr/dts/arm/st/h7rs/stm32h7rs.dtsi:36 */

		/* node '/cpus/cpu@0' defined in zephyr/dts/arm/st/h7rs/stm32h7rs.dtsi:38 */
		cpu0: cpu@0 {
			device_type = "cpu";          /* in zephyr/dts/arm/st/h7rs/stm32h7rs.dtsi:39 */
			compatible = "arm,cortex-m7"; /* in zephyr/dts/arm/st/h7rs/stm32h7rs.dtsi:40 */
			reg = < 0x0 >;                /* in zephyr/dts/arm/st/h7rs/stm32h7rs.dtsi:41 */
			#address-cells = < 0x1 >;     /* in zephyr/dts/arm/st/h7rs/stm32h7rs.dtsi:42 */
			#size-cells = < 0x1 >;        /* in zephyr/dts/arm/st/h7rs/stm32h7rs.dtsi:43 */

			/* node '/cpus/cpu@0/mpu@e000ed90' defined in zephyr/dts/arm/st/h7rs/stm32h7rs.dtsi:45 */
			mpu: mpu@e000ed90 {
				compatible = "arm,armv7m-mpu"; /* in zephyr/dts/arm/st/h7rs/stm32h7rs.dtsi:46 */
				reg = < 0xe000ed90 0x40 >;     /* in zephyr/dts/arm/st/h7rs/stm32h7rs.dtsi:47 */
			};
		};
	};

	/* node '/memory@24000000' defined in zephyr/dts/arm/st/h7rs/stm32h7rs.dtsi:53 */
	sram0: memory@24000000 {
		reg = < 0x24000000 0x72000 >;        /* in zephyr/dts/arm/st/h7rs/stm32h7rs.dtsi:54 */
		compatible = "zephyr,memory-region",
		             "mmio-sram";            /* in zephyr/dts/arm/st/h7rs/stm32h7rs.dtsi:55 */
		zephyr,memory-region = "SRAM0";      /* in zephyr/dts/arm/st/h7rs/stm32h7rs.dtsi:56 */
	};

	/* node '/memory@30000000' defined in zephyr/dts/arm/st/h7rs/stm32h7rs.dtsi:60 */
	sram1: memory@30000000 {
		reg = < 0x30000000 0x4000 >;         /* in zephyr/dts/arm/st/h7rs/stm32h7rs.dtsi:61 */
		compatible = "zephyr,memory-region",
		             "mmio-sram";            /* in zephyr/dts/arm/st/h7rs/stm32h7rs.dtsi:62 */
		zephyr,memory-region = "SRAM1";      /* in zephyr/dts/arm/st/h7rs/stm32h7rs.dtsi:63 */
		zephyr,memory-attr = < 0x100000 >;   /* in zephyr/dts/arm/st/h7rs/stm32h7rs.dtsi:64 */
	};

	/* node '/memory@30004000' defined in zephyr/dts/arm/st/h7rs/stm32h7rs.dtsi:68 */
	sram2: memory@30004000 {
		compatible = "zephyr,memory-region",
		             "mmio-sram";            /* in zephyr/dts/arm/st/h7rs/stm32h7rs.dtsi:69 */
		reg = < 0x30004000 0x4000 >;         /* in zephyr/dts/arm/st/h7rs/stm32h7rs.dtsi:70 */
		zephyr,memory-region = "SRAM2";      /* in zephyr/dts/arm/st/h7rs/stm32h7rs.dtsi:71 */
		status = "disabled";                 /* in zephyr/dts/arm/st/h7rs/stm32h7rs.dtsi:76 */
	};

	/* node '/memory@20000000' defined in zephyr/dts/arm/st/h7rs/stm32h7rs.dtsi:79 */
	dtcm: memory@20000000 {
		compatible = "zephyr,memory-region",
		             "arm,dtcm";             /* in zephyr/dts/arm/st/h7rs/stm32h7rs.dtsi:80 */
		reg = < 0x20000000 0x20000 >;        /* in zephyr/dts/arm/st/h7rs/stm32h7rs.dtsi:81 */
		zephyr,memory-region = "DTCM";       /* in zephyr/dts/arm/st/h7rs/stm32h7rs.dtsi:82 */
	};

	/* node '/memory@0' defined in zephyr/dts/arm/st/h7rs/stm32h7rs.dtsi:85 */
	itcm: memory@0 {
		compatible = "zephyr,memory-region",
		             "arm,itcm";             /* in zephyr/dts/arm/st/h7rs/stm32h7rs.dtsi:86 */
		reg = < 0x0 0x10000 >;               /* in zephyr/dts/arm/st/h7rs/stm32h7rs.dtsi:87 */
		zephyr,memory-region = "ITCM";       /* in zephyr/dts/arm/st/h7rs/stm32h7rs.dtsi:88 */
	};

	/* node '/memory@70000000' defined in zephyr/dts/arm/st/h7rs/stm32h7rs.dtsi:91 */
	ext_memory: ext_flash_mem: memory@70000000 {
		compatible = "zephyr,memory-region"; /* in zephyr/boards/st/stm32h7s78_dk/stm32h7s78_dk-common.dtsi:75 */
		reg = < 0x70000000 0x8000000 >;      /* in zephyr/boards/st/stm32h7s78_dk/stm32h7s78_dk-common.dtsi:76 */
		zephyr,memory-region = "EXTMEM";     /* in zephyr/boards/st/stm32h7s78_dk/stm32h7s78_dk-common.dtsi:77 */
		zephyr,memory-attr = < 0x1000000 >;  /* in zephyr/boards/st/stm32h7s78_dk/stm32h7s78_dk-common.dtsi:79 */
	};

	/* node '/clocks' defined in zephyr/dts/arm/st/h7rs/stm32h7rs.dtsi:99 */
	clocks {
		#address-cells = < 0x1 >; /* in zephyr/dts/arm/st/h7rs/stm32h7rs.dtsi:100 */
		#size-cells = < 0x0 >;    /* in zephyr/dts/arm/st/h7rs/stm32h7rs.dtsi:101 */

		/* node '/clocks/clk-hse' defined in zephyr/dts/arm/st/h7rs/stm32h7rs.dtsi:103 */
		clk_hse: clk-hse {
			#clock-cells = < 0x0 >;            /* in zephyr/dts/arm/st/h7rs/stm32h7rs.dtsi:104 */
			compatible = "st,stm32-hse-clock"; /* in zephyr/dts/arm/st/h7rs/stm32h7rs.dtsi:105 */
			clock-frequency = < 0x16e3600 >;   /* in zephyr/boards/st/stm32h7s78_dk/stm32h7s78_dk-common.dtsi:92 */
			hse-bypass;                        /* in zephyr/boards/st/stm32h7s78_dk/stm32h7s78_dk-common.dtsi:93 */
			status = "okay";                   /* in zephyr/boards/st/stm32h7s78_dk/stm32h7s78_dk-common.dtsi:94 */
			phandle = < 0x54 >;                /* in zephyr/boards/st/stm32h7s78_dk/stm32h7s78_dk-common.dtsi:105 */
		};

		/* node '/clocks/clk-hsi' defined in zephyr/dts/arm/st/h7rs/stm32h7rs.dtsi:109 */
		clk_hsi: clk-hsi {
			#clock-cells = < 0x0 >;              /* in zephyr/dts/arm/st/h7rs/stm32h7rs.dtsi:110 */
			compatible = "st,stm32h7-hsi-clock"; /* in zephyr/dts/arm/st/h7rs/stm32h7rs.dtsi:111 */
			hsi-div = < 0x1 >;                   /* in zephyr/dts/arm/st/h7rs/stm32h7rs.dtsi:112 */
			clock-frequency = < 0x3d09000 >;     /* in zephyr/dts/arm/st/h7rs/stm32h7rs.dtsi:113 */
			status = "disabled";                 /* in zephyr/dts/arm/st/h7rs/stm32h7rs.dtsi:114 */
		};

		/* node '/clocks/clk-hsi48' defined in zephyr/dts/arm/st/h7rs/stm32h7rs.dtsi:117 */
		clk_hsi48: clk-hsi48 {
			#clock-cells = < 0x0 >;          /* in zephyr/dts/arm/st/h7rs/stm32h7rs.dtsi:118 */
			compatible = "fixed-clock";      /* in zephyr/dts/arm/st/h7rs/stm32h7rs.dtsi:119 */
			clock-frequency = < 0x2dc6c00 >; /* in zephyr/dts/arm/st/h7rs/stm32h7rs.dtsi:120 */
			status = "okay";                 /* in zephyr/boards/st/stm32h7s78_dk/stm32h7s78_dk-common.dtsi:84 */
		};

		/* node '/clocks/clk-csi' defined in zephyr/dts/arm/st/h7rs/stm32h7rs.dtsi:124 */
		clk_csi: clk-csi {
			#clock-cells = < 0x0 >;         /* in zephyr/dts/arm/st/h7rs/stm32h7rs.dtsi:125 */
			compatible = "fixed-clock";     /* in zephyr/dts/arm/st/h7rs/stm32h7rs.dtsi:126 */
			clock-frequency = < 0x3d0900 >; /* in zephyr/dts/arm/st/h7rs/stm32h7rs.dtsi:127 */
			status = "disabled";            /* in zephyr/dts/arm/st/h7rs/stm32h7rs.dtsi:128 */
		};

		/* node '/clocks/clk-lse' defined in zephyr/dts/arm/st/h7rs/stm32h7rs.dtsi:131 */
		clk_lse: clk-lse {
			#clock-cells = < 0x0 >;            /* in zephyr/dts/arm/st/h7rs/stm32h7rs.dtsi:132 */
			compatible = "st,stm32-lse-clock"; /* in zephyr/dts/arm/st/h7rs/stm32h7rs.dtsi:133 */
			clock-frequency = < 0x8000 >;      /* in zephyr/dts/arm/st/h7rs/stm32h7rs.dtsi:134 */
			driving-capability = < 0x0 >;      /* in zephyr/dts/arm/st/h7rs/stm32h7rs.dtsi:135 */
			status = "okay";                   /* in zephyr/boards/st/stm32h7s78_dk/stm32h7s78_dk-common.dtsi:88 */
		};

		/* node '/clocks/clk-lsi' defined in zephyr/dts/arm/st/h7rs/stm32h7rs.dtsi:139 */
		clk_lsi: clk-lsi {
			#clock-cells = < 0x0 >;       /* in zephyr/dts/arm/st/h7rs/stm32h7rs.dtsi:140 */
			compatible = "fixed-clock";   /* in zephyr/dts/arm/st/h7rs/stm32h7rs.dtsi:141 */
			clock-frequency = < 0x7d00 >; /* in zephyr/dts/arm/st/h7rs/stm32h7rs.dtsi:142 */
			status = "disabled";          /* in zephyr/dts/arm/st/h7rs/stm32h7rs.dtsi:143 */
		};

		/* node '/clocks/pll@0' defined in zephyr/dts/arm/st/h7rs/stm32h7rs.dtsi:146 */
		pll: pll@0 {
			#clock-cells = < 0x0 >;                /* in zephyr/dts/arm/st/h7rs/stm32h7rs.dtsi:147 */
			compatible = "st,stm32h7rs-pll-clock"; /* in zephyr/dts/arm/st/h7rs/stm32h7rs.dtsi:148 */
			reg = < 0x0 >;                         /* in zephyr/dts/arm/st/h7rs/stm32h7rs.dtsi:149 */
			div-m = < 0xc >;                       /* in zephyr/boards/st/stm32h7s78_dk/stm32h7s78_dk-common.dtsi:98 */
			mul-n = < 0xfa >;                      /* in zephyr/boards/st/stm32h7s78_dk/stm32h7s78_dk-common.dtsi:99 */
			div-p = < 0x2 >;                       /* in zephyr/boards/st/stm32h7s78_dk/stm32h7s78_dk-common.dtsi:100 */
			div-q = < 0x2 >;                       /* in zephyr/boards/st/stm32h7s78_dk/stm32h7s78_dk-common.dtsi:101 */
			div-r = < 0x2 >;                       /* in zephyr/boards/st/stm32h7s78_dk/stm32h7s78_dk-common.dtsi:102 */
			div-s = < 0x2 >;                       /* in zephyr/boards/st/stm32h7s78_dk/stm32h7s78_dk-common.dtsi:103 */
			div-t = < 0x2 >;                       /* in zephyr/boards/st/stm32h7s78_dk/stm32h7s78_dk-common.dtsi:104 */
			clocks = < &clk_hse >;                 /* in zephyr/boards/st/stm32h7s78_dk/stm32h7s78_dk-common.dtsi:105 */
			status = "okay";                       /* in zephyr/boards/st/stm32h7s78_dk/stm32h7s78_dk-common.dtsi:106 */
			phandle = < 0x2 >;                     /* in zephyr/boards/st/stm32h7s78_dk/stm32h7s78_dk-common.dtsi:118 */
		};

		/* node '/clocks/pll@1' defined in zephyr/dts/arm/st/h7rs/stm32h7rs.dtsi:153 */
		pll2: pll@1 {
			#clock-cells = < 0x0 >;                /* in zephyr/dts/arm/st/h7rs/stm32h7rs.dtsi:154 */
			compatible = "st,stm32h7rs-pll-clock"; /* in zephyr/dts/arm/st/h7rs/stm32h7rs.dtsi:155 */
			reg = < 0x1 >;                         /* in zephyr/dts/arm/st/h7rs/stm32h7rs.dtsi:156 */
			status = "disabled";                   /* in zephyr/dts/arm/st/h7rs/stm32h7rs.dtsi:157 */
		};

		/* node '/clocks/pll@2' defined in zephyr/dts/arm/st/h7rs/stm32h7rs.dtsi:160 */
		pll3: pll@2 {
			#clock-cells = < 0x0 >;                /* in zephyr/dts/arm/st/h7rs/stm32h7rs.dtsi:161 */
			compatible = "st,stm32h7rs-pll-clock"; /* in zephyr/dts/arm/st/h7rs/stm32h7rs.dtsi:162 */
			reg = < 0x2 >;                         /* in zephyr/dts/arm/st/h7rs/stm32h7rs.dtsi:163 */
			div-m = < 0xc >;                       /* in zephyr/boards/st/stm32h7s78_dk/stm32h7s78_dk-common.dtsi:110 */
			mul-n = < 0x19 >;                      /* in zephyr/boards/st/stm32h7s78_dk/stm32h7s78_dk-common.dtsi:111 */
			div-r = < 0x2 >;                       /* in zephyr/boards/st/stm32h7s78_dk/stm32h7s78_dk-common.dtsi:112 */
			clocks = < &clk_hse >;                 /* in zephyr/boards/st/stm32h7s78_dk/stm32h7s78_dk-common.dtsi:113 */
			status = "okay";                       /* in zephyr/boards/st/stm32h7s78_dk/stm32h7s78_dk-common.dtsi:114 */
		};

		/* node '/clocks/perck' defined in zephyr/dts/arm/st/h7rs/stm32h7rs.dtsi:167 */
		perck: perck {
			#clock-cells = < 0x0 >;            /* in zephyr/dts/arm/st/h7rs/stm32h7rs.dtsi:168 */
			compatible = "st,stm32-clock-mux"; /* in zephyr/dts/arm/st/h7rs/stm32h7rs.dtsi:169 */
			status = "disabled";               /* in zephyr/dts/arm/st/h7rs/stm32h7rs.dtsi:170 */
		};
	};

	/* node '/mcos' defined in zephyr/dts/arm/st/h7rs/stm32h7rs.dtsi:174 */
	mcos {

		/* node '/mcos/mco1' defined in zephyr/dts/arm/st/h7rs/stm32h7rs.dtsi:175 */
		mco1: mco1 {
			compatible = "st,stm32-clock-mco"; /* in zephyr/dts/arm/st/h7rs/stm32h7rs.dtsi:176 */
			status = "disabled";               /* in zephyr/dts/arm/st/h7rs/stm32h7rs.dtsi:177 */
		};

		/* node '/mcos/mco2' defined in zephyr/dts/arm/st/h7rs/stm32h7rs.dtsi:180 */
		mco2: mco2 {
			compatible = "st,stm32-clock-mco"; /* in zephyr/dts/arm/st/h7rs/stm32h7rs.dtsi:181 */
			status = "disabled";               /* in zephyr/dts/arm/st/h7rs/stm32h7rs.dtsi:182 */
		};
	};

	/* node '/otgfs_phy' defined in zephyr/dts/arm/st/h7rs/stm32h7rs.dtsi:951 */
	otgfs_phy: otgfs_phy {
		compatible = "usb-nop-xceiv"; /* in zephyr/dts/arm/st/h7rs/stm32h7rs.dtsi:952 */
		#phy-cells = < 0x0 >;         /* in zephyr/dts/arm/st/h7rs/stm32h7rs.dtsi:953 */
		phandle = < 0x33 >;           /* in zephyr/dts/arm/st/h7rs/stm32h7rs.dtsi:896 */
	};

	/* node '/dietemp' defined in zephyr/dts/arm/st/h7rs/stm32h7rs.dtsi:956 */
	die_temp: dietemp {
		compatible = "st,stm32-temp-cal"; /* in zephyr/dts/arm/st/h7rs/stm32h7rs.dtsi:957 */
		ts-cal1-addr = < 0x8fff814 >;     /* in zephyr/dts/arm/st/h7rs/stm32h7rs.dtsi:958 */
		ts-cal2-addr = < 0x8fff818 >;     /* in zephyr/dts/arm/st/h7rs/stm32h7rs.dtsi:959 */
		ts-cal1-temp = < 0x1e >;          /* in zephyr/dts/arm/st/h7rs/stm32h7rs.dtsi:960 */
		ts-cal2-temp = < 0x82 >;          /* in zephyr/dts/arm/st/h7rs/stm32h7rs.dtsi:961 */
		ts-cal-vrefanalog = < 0xce4 >;    /* in zephyr/dts/arm/st/h7rs/stm32h7rs.dtsi:962 */
		ts-cal-resolution = < 0xc >;      /* in zephyr/dts/arm/st/h7rs/stm32h7rs.dtsi:963 */
		io-channels = < &adc1 0x10 >;     /* in zephyr/dts/arm/st/h7rs/stm32h7rs.dtsi:964 */
		status = "okay";                  /* in zephyr/boards/st/stm32h7s78_dk/stm32h7s78_dk-common.dtsi:281 */
	};

	/* node '/vbat' defined in zephyr/dts/arm/st/h7rs/stm32h7rs.dtsi:968 */
	vbat: vbat {
		compatible = "st,stm32-vbat"; /* in zephyr/dts/arm/st/h7rs/stm32h7rs.dtsi:969 */
		ratio = < 0x4 >;              /* in zephyr/dts/arm/st/h7rs/stm32h7rs.dtsi:970 */
		io-channels = < &adc2 0x10 >; /* in zephyr/dts/arm/st/h7rs/stm32h7rs.dtsi:972 */
		status = "okay";              /* in zephyr/boards/st/stm32h7s78_dk/stm32h7s78_dk-common.dtsi:289 */
	};

	/* node '/vref' defined in zephyr/dts/arm/st/h7rs/stm32h7rs.dtsi:975 */
	vref: vref {
		compatible = "st,stm32-vref";     /* in zephyr/dts/arm/st/h7rs/stm32h7rs.dtsi:976 */
		vrefint-cal-addr = < 0x8fff810 >; /* in zephyr/dts/arm/st/h7rs/stm32h7rs.dtsi:977 */
		vrefint-cal-mv = < 0xce4 >;       /* in zephyr/dts/arm/st/h7rs/stm32h7rs.dtsi:978 */
		io-channels = < &adc1 0x11 >;     /* in zephyr/dts/arm/st/h7rs/stm32h7rs.dtsi:980 */
		status = "okay";                  /* in zephyr/boards/st/stm32h7s78_dk/stm32h7s78_dk-common.dtsi:285 */
	};

	/* node '/connector' defined in zephyr/boards/st/stm32h7s78_dk/arduino_r3_connector.dtsi:10 */
	arduino_header: connector {
		compatible = "arduino-header-r3";          /* in zephyr/boards/st/stm32h7s78_dk/arduino_r3_connector.dtsi:11 */
		#gpio-cells = < 0x2 >;                     /* in zephyr/boards/st/stm32h7s78_dk/arduino_r3_connector.dtsi:12 */
		gpio-map-mask = < 0xffffffff 0xffffffc0 >; /* in zephyr/boards/st/stm32h7s78_dk/arduino_r3_connector.dtsi:13 */
		gpio-map-pass-thru = < 0x0 0x3f >;         /* in zephyr/boards/st/stm32h7s78_dk/arduino_r3_connector.dtsi:14 */
		gpio-map = < 0x0 0x0 &gpioc 0x0 0x0 >,
		           < 0x1 0x0 &gpioc 0x2 0x0 >,
		           < 0x2 0x0 &gpioc 0x3 0x0 >,
		           < 0x3 0x0 &gpiof 0xc 0x0 >,
		           < 0x4 0x0 &gpiof 0xd 0x0 >,
		           < 0x5 0x0 &gpioc 0x1 0x0 >,
		           < 0x6 0x0 &gpioe 0x7 0x0 >,
		           < 0x7 0x0 &gpioe 0x8 0x0 >,
		           < 0x8 0x0 &gpiof 0x1 0x0 >,
		           < 0x9 0x0 &gpiod 0xc 0x0 >,
		           < 0xa 0x0 &gpiof 0x2 0x0 >,
		           < 0xb 0x0 &gpiod 0xd 0x0 >,
		           < 0xc 0x0 &gpiod 0xf 0x0 >,
		           < 0xd 0x0 &gpiof 0x3 0x0 >,
		           < 0xe 0x0 &gpiof 0x4 0x0 >,
		           < 0xf 0x0 &gpiof 0x6 0x0 >,
		           < 0x10 0x0 &gpiof 0x8 0x0 >,
		           < 0x11 0x0 &gpioe 0xe 0x0 >,
		           < 0x12 0x0 &gpioe 0xd 0x0 >,
		           < 0x13 0x0 &gpioe 0xc 0x0 >,
		           < 0x14 0x0 &gpiob 0x9 0x0 >,
		           < 0x15 0x0 &gpiob 0x6 0x0 >;    /* in zephyr/boards/st/stm32h7s78_dk/arduino_r3_connector.dtsi:15 */
	};

	/* node '/memory@90000000' defined in zephyr/boards/st/stm32h7s78_dk/stm32h7s78_dk-common.dtsi:23 */
	psram: memory@90000000 {
		compatible = "zephyr,memory-region"; /* in zephyr/boards/st/stm32h7s78_dk/stm32h7s78_dk-common.dtsi:24 */
		reg = < 0x90000000 0x2000000 >;      /* in zephyr/boards/st/stm32h7s78_dk/stm32h7s78_dk-common.dtsi:25 */
		zephyr,memory-region = "PSRAM";      /* in zephyr/boards/st/stm32h7s78_dk/stm32h7s78_dk-common.dtsi:26 */
		zephyr,memory-attr = < 0x100000 >;   /* in zephyr/boards/st/stm32h7s78_dk/stm32h7s78_dk-common.dtsi:27 */
	};

	/* node '/leds' defined in zephyr/boards/st/stm32h7s78_dk/stm32h7s78_dk-common.dtsi:30 */
	leds {
		compatible = "gpio-leds"; /* in zephyr/boards/st/stm32h7s78_dk/stm32h7s78_dk-common.dtsi:31 */

		/* node '/leds/led_1' defined in zephyr/boards/st/stm32h7s78_dk/stm32h7s78_dk-common.dtsi:33 */
		green_led: led_1 {
			gpios = < &gpioo 0x1 0x1 >; /* in zephyr/boards/st/stm32h7s78_dk/stm32h7s78_dk-common.dtsi:34 */
			label = "User LD1";         /* in zephyr/boards/st/stm32h7s78_dk/stm32h7s78_dk-common.dtsi:35 */
		};

		/* node '/leds/led_2' defined in zephyr/boards/st/stm32h7s78_dk/stm32h7s78_dk-common.dtsi:38 */
		orange_led: led_2 {
			gpios = < &gpioo 0x5 0x1 >; /* in zephyr/boards/st/stm32h7s78_dk/stm32h7s78_dk-common.dtsi:39 */
			label = "User LD2";         /* in zephyr/boards/st/stm32h7s78_dk/stm32h7s78_dk-common.dtsi:40 */
		};

		/* node '/leds/led_3' defined in zephyr/boards/st/stm32h7s78_dk/stm32h7s78_dk-common.dtsi:43 */
		red_led: led_3 {
			gpios = < &gpiom 0x2 0x1 >; /* in zephyr/boards/st/stm32h7s78_dk/stm32h7s78_dk-common.dtsi:44 */
			label = "User LD3";         /* in zephyr/boards/st/stm32h7s78_dk/stm32h7s78_dk-common.dtsi:45 */
		};

		/* node '/leds/led_4' defined in zephyr/boards/st/stm32h7s78_dk/stm32h7s78_dk-common.dtsi:48 */
		blue_led: led_4 {
			gpios = < &gpiom 0x3 0x1 >; /* in zephyr/boards/st/stm32h7s78_dk/stm32h7s78_dk-common.dtsi:49 */
			label = "User LD4";         /* in zephyr/boards/st/stm32h7s78_dk/stm32h7s78_dk-common.dtsi:50 */
		};
	};

	/* node '/gpio_keys' defined in zephyr/boards/st/stm32h7s78_dk/stm32h7s78_dk-common.dtsi:54 */
	gpio_keys {
		compatible = "gpio-keys"; /* in zephyr/boards/st/stm32h7s78_dk/stm32h7s78_dk-common.dtsi:55 */

		/* node '/gpio_keys/button' defined in zephyr/boards/st/stm32h7s78_dk/stm32h7s78_dk-common.dtsi:57 */
		user_button: button {
			label = "User";             /* in zephyr/boards/st/stm32h7s78_dk/stm32h7s78_dk-common.dtsi:58 */
			gpios = < &gpioc 0xd 0x1 >; /* in zephyr/boards/st/stm32h7s78_dk/stm32h7s78_dk-common.dtsi:59 */
			zephyr,code = < 0xb >;      /* in zephyr/boards/st/stm32h7s78_dk/stm32h7s78_dk-common.dtsi:60 */
		};
	};
};
